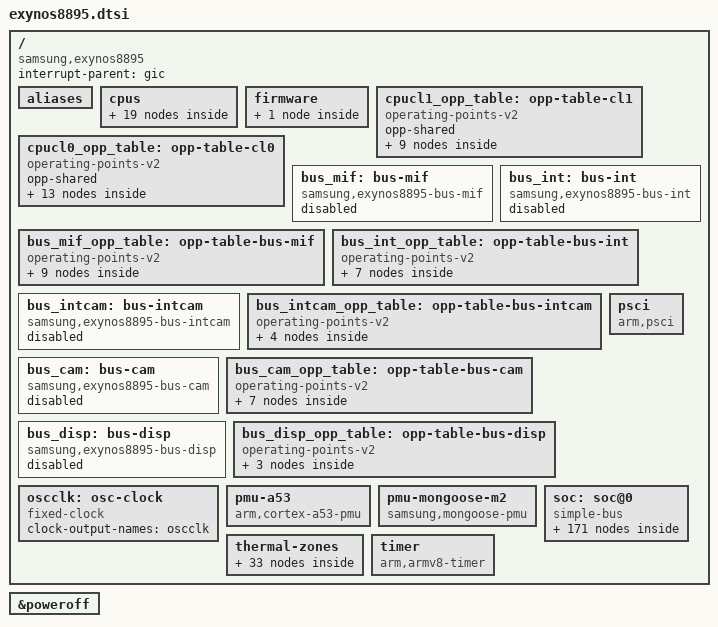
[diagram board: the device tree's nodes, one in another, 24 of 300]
// SPDX-License-Identifier: GPL-2.0 OR BSD-3-Clause
/*
 * Samsung's Exynos 8895 SoC device tree source
 *
 * Copyright (c) 2024, Ivaylo Ivanov <ivo.ivanov.ivanov1@gmail.com>
 */

#include <dt-bindings/clock/samsung,exynos8895.h>
#include <dt-bindings/clock/samsung,exynos8895-acpm.h>
#include <dt-bindings/interrupt-controller/arm-gic.h>
#include <dt-bindings/thermal/thermal.h>

/ {
	compatible = "samsung,exynos8895";
	#address-cells = <2>;
	#size-cells = <1>;

	interrupt-parent = <&gic>;

	aliases {
		pinctrl0 = &pinctrl_alive;
		pinctrl1 = &pinctrl_abox;
		pinctrl2 = &pinctrl_vts;
		pinctrl3 = &pinctrl_fsys0;
		pinctrl4 = &pinctrl_fsys1;
		pinctrl5 = &pinctrl_busc;
		pinctrl6 = &pinctrl_peric0;
		pinctrl7 = &pinctrl_peric1;
	};

	cpus {
		#address-cells = <1>;
		#size-cells = <0>;

		cpu-map {
			cluster0 {
				core0 { cpu = <&cpu0>; };
				core1 { cpu = <&cpu1>; };
				core2 { cpu = <&cpu2>; };
				core3 { cpu = <&cpu3>; };
			};

			cluster1 {
				core0 { cpu = <&cpu4>; };
				core1 { cpu = <&cpu5>; };
				core2 { cpu = <&cpu6>; };
				core3 { cpu = <&cpu7>; };
			};
		};

		/* Boot cluster (Cortex-A53, MPIDR Aff1=1) first: stock logical ids 0-3. */
		cpu0: cpu@100 {
			device_type = "cpu";
			compatible = "arm,cortex-a53";
			reg = <0x100>;			/* S:arch/arm64/boot/dts/exynos/exynos8895.dtsi:184, FDT:4274 */
			enable-method = "psci";		/* S:arch/arm64/boot/dts/exynos/exynos8895.dtsi:186 */
			capacity-dmips-mhz = <2048>;	/* S:arch/arm64/kernel/topology.c:207 */
		};

		cpu1: cpu@101 {
			device_type = "cpu";
			compatible = "arm,cortex-a53";
			reg = <0x101>;			/* S:arch/arm64/boot/dts/exynos/exynos8895.dtsi:194 */
			enable-method = "psci";
			capacity-dmips-mhz = <2048>;
		};

		cpu2: cpu@102 {
			device_type = "cpu";
			compatible = "arm,cortex-a53";
			reg = <0x102>;			/* S:arch/arm64/boot/dts/exynos/exynos8895.dtsi:203 */
			enable-method = "psci";
			capacity-dmips-mhz = <2048>;
		};

		cpu3: cpu@103 {
			device_type = "cpu";
			compatible = "arm,cortex-a53";
			reg = <0x103>;			/* S:arch/arm64/boot/dts/exynos/exynos8895.dtsi:212 */
			enable-method = "psci";
			capacity-dmips-mhz = <2048>;
		};

		/* Mongoose M2 cluster (MPIDR Aff1=0): stock logical ids 4-7. */
		cpu4: cpu@0 {
			device_type = "cpu";
			compatible = "samsung,mongoose-m2";	/* A:Documentation/devicetree/bindings/arm/cpus.yaml:222 */
			reg = <0x0>;			/* S:arch/arm64/boot/dts/exynos/exynos8895.dtsi:221, FDT:4317 */
			enable-method = "psci";		/* S:arch/arm64/boot/dts/exynos/exynos8895.dtsi:223 */
			capacity-dmips-mhz = <5035>;	/* S:arch/arm64/kernel/topology.c:205 */
		};

		cpu5: cpu@1 {
			device_type = "cpu";
			compatible = "samsung,mongoose-m2";
			reg = <0x1>;			/* S:arch/arm64/boot/dts/exynos/exynos8895.dtsi:231 */
			enable-method = "psci";
			capacity-dmips-mhz = <5035>;
		};

		cpu6: cpu@2 {
			device_type = "cpu";
			compatible = "samsung,mongoose-m2";
			reg = <0x2>;			/* S:arch/arm64/boot/dts/exynos/exynos8895.dtsi:240 */
			enable-method = "psci";
			capacity-dmips-mhz = <5035>;
		};

		cpu7: cpu@3 {
			device_type = "cpu";
			compatible = "samsung,mongoose-m2";
			reg = <0x3>;			/* S:arch/arm64/boot/dts/exynos/exynos8895.dtsi:249 */
			enable-method = "psci";
			capacity-dmips-mhz = <5035>;
		};
	};

	firmware {
		/*
		 * The APM's ACPM firmware interface (the stock acpm_ipc, acpm and
		 * acpm_dvfs nodes, S:arch/arm64/boot/dts/exynos/exynos8895.dtsi:2407-2438,
		 * FDT:6674-6701; their channel numbers are driver match data here).
		 * The PMIC child is the board's.
		 */
		acpm_ipc: power-management {
			compatible = "samsung,exynos8895-acpm-ipc";
			#clock-cells = <1>;	/* DVFS clocks, dt-bindings/clock/samsung,exynos8895-acpm.h */
			mboxes = <&ap2apm_mailbox>;
			shmem = <&apm_sram>;
			status = "disabled";
		};
	};

	/*
	 * Cortex-A53 cluster, cpus 0-3 = ACPM DVFS domain cpucl1. Levels: the ECT
	 * dvfs_cpucl1 table (sboot.bin SB+0x463cc); every ASV table (versions 1-8)
	 * enables L3..L11 = 1690000..455000 kHz, and stock "min-freq = <455000>;"
	 * (S:arch/arm64/boot/dts/exynos/exynos8895.dtsi:473). Nine levels = the
	 * nine A53 "current" entries (:189). No opp-microvolt: the APM applies
	 * the voltage itself, and there is no cpu-supply.
	 * clock-latency: S:drivers/cpufreq/exynos-acme.h:101 "#define TRANSITION_LATENCY 100000" (ns).
	 */
	cpucl1_opp_table: opp-table-cl1 {
		compatible = "operating-points-v2";
		opp-shared;

		opp-455000000 {
			opp-hz = /bits/ 64 <455000000>;
			clock-latency-ns = <100000>;
		};
		opp-598000000 {
			opp-hz = /bits/ 64 <598000000>;
			clock-latency-ns = <100000>;
		};
		opp-715000000 {
			opp-hz = /bits/ 64 <715000000>;
			clock-latency-ns = <100000>;
		};
		opp-832000000 {
			opp-hz = /bits/ 64 <832000000>;
			clock-latency-ns = <100000>;
		};
		opp-949000000 {
			opp-hz = /bits/ 64 <949000000>;
			clock-latency-ns = <100000>;
		};
		opp-1053000000 {
			/* ASV boot level L6 */
			opp-hz = /bits/ 64 <1053000000>;
			clock-latency-ns = <100000>;
		};
		opp-1248000000 {
			opp-hz = /bits/ 64 <1248000000>;
			clock-latency-ns = <100000>;
		};
		opp-1456000000 {
			opp-hz = /bits/ 64 <1456000000>;
			clock-latency-ns = <100000>;
		};
		opp-1690000000 {
			opp-hz = /bits/ 64 <1690000000>;
			clock-latency-ns = <100000>;
		};
	};

	/*
	 * Mongoose cluster, cpus 4-7 = ACPM DVFS domain cpucl0. Levels: the ECT
	 * dvfs_cpucl0 table (SB+0x462d4); ASV tables 3-8 enable L5..L17 =
	 * 2314000..741000 kHz (tables 1-2 stop at 2158000, and stock uses table 8
	 * for a version without a table, S:drivers/soc/samsung/cal-if/vclk.c:507-520),
	 * stock "min-freq = <741000>;" (S:arch/arm64/boot/dts/exynos/exynos8895.dtsi:518).
	 * 13 levels = the Mongoose "current" entries (:226). Drop opp-2314000000
	 * only if the fused ASV version (acpm-clk "asv_ver=") is 1 or 2.
	 * opp-microvolt feeds only the energy model of the IPA power actor (no
	 * cpu-supply, so the OPP core never applies it; the APM keeps its own
	 * voltage): ECT ASV block, dvfs_cpucl0, table version 8, group 0 (the
	 * highest voltage of each level in that table; Lnn = ECT level), chosen
	 * because ACK has no static-power term (spec/L2c_thermal.md 4.3).
	 */
	cpucl0_opp_table: opp-table-cl0 {
		compatible = "operating-points-v2";
		opp-shared;

		opp-741000000 {
			opp-hz = /bits/ 64 <741000000>;
			opp-microvolt = <681250>;	/* L17 */
			clock-latency-ns = <100000>;
		};
		opp-858000000 {
			opp-hz = /bits/ 64 <858000000>;
			opp-microvolt = <706250>;	/* L16 */
			clock-latency-ns = <100000>;
		};
		opp-962000000 {
			opp-hz = /bits/ 64 <962000000>;
			opp-microvolt = <725000>;	/* L15 */
			clock-latency-ns = <100000>;
		};
		opp-1066000000 {
			/* ASV boot level L14 */
			opp-hz = /bits/ 64 <1066000000>;
			opp-microvolt = <737500>;	/* L14 */
			clock-latency-ns = <100000>;
		};
		opp-1170000000 {
			opp-hz = /bits/ 64 <1170000000>;
			opp-microvolt = <756250>;	/* L13 */
			clock-latency-ns = <100000>;
		};
		opp-1261000000 {
			opp-hz = /bits/ 64 <1261000000>;
			opp-microvolt = <775000>;	/* L12 */
			clock-latency-ns = <100000>;
		};
		opp-1469000000 {
			opp-hz = /bits/ 64 <1469000000>;
			opp-microvolt = <825000>;	/* L11 */
			clock-latency-ns = <100000>;
		};
		opp-1703000000 {
			opp-hz = /bits/ 64 <1703000000>;
			opp-microvolt = <893750>;	/* L10 */
			clock-latency-ns = <100000>;
		};
		opp-1807000000 {
			opp-hz = /bits/ 64 <1807000000>;
			opp-microvolt = <925000>;	/* L9 */
			clock-latency-ns = <100000>;
		};
		opp-1937000000 {
			opp-hz = /bits/ 64 <1937000000>;
			opp-microvolt = <968750>;	/* L8 */
			clock-latency-ns = <100000>;
		};
		opp-2002000000 {
			opp-hz = /bits/ 64 <2002000000>;
			opp-microvolt = <987500>;	/* L7 */
			clock-latency-ns = <100000>;
		};
		opp-2158000000 {
			opp-hz = /bits/ 64 <2158000000>;
			opp-microvolt = <1050000>;	/* L6 */
			clock-latency-ns = <100000>;
		};
		opp-2314000000 {
			opp-hz = /bits/ 64 <2314000000>;
			opp-microvolt = <1118750>;	/* L5 */
			clock-latency-ns = <100000>;
		};
	};

	/*
	 * Bus DVFS domains (spec L2b 4.1): stock devfreq_{mif,int,intcam,disp,cam}
	 * (FDT:6712-6805). Levels = ECT DVFS levels inside the ASV-enabled range,
	 * the same for ASV tables 1-8 (sboot.bin ECT, spec L2b 0.4). The rate is
	 * set through the ACPM DVFS clock (FREQ_REQ on ACPM channel 0).
	 */
	bus_mif: bus-mif {
		compatible = "samsung,exynos8895-bus-mif";
		clocks = <&acpm_ipc EXYNOS8895_CLK_ACPM_DVFS_MIF>;	/* dfs_id 0xb040000, FDT:6728 */
		operating-points-v2 = <&bus_mif_opp_table>;
		status = "disabled";
	};

	bus_mif_opp_table: opp-table-bus-mif {
		compatible = "operating-points-v2";

		/* ECT dvfs_mif L10..L2 (SB:0x46508); ASV level_en L2-L10 in tables 1-8 */
		opp-286000000 { opp-hz = /bits/ 64 <286000000>; };
		opp-421000000 { opp-hz = /bits/ 64 <421000000>; };
		opp-546000000 { opp-hz = /bits/ 64 <546000000>; };
		opp-676000000 { opp-hz = /bits/ 64 <676000000>; };
		opp-845000000 { opp-hz = /bits/ 64 <845000000>; };
		opp-1014000000 { opp-hz = /bits/ 64 <1014000000>; };
		opp-1352000000 { opp-hz = /bits/ 64 <1352000000>; };
		opp-1540000000 { opp-hz = /bits/ 64 <1540000000>; };
		opp-1794000000 { opp-hz = /bits/ 64 <1794000000>; };
	};

	bus_int: bus-int {
		compatible = "samsung,exynos8895-bus-int";
		clocks = <&acpm_ipc EXYNOS8895_CLK_ACPM_DVFS_INT>;	/* dfs_id 0xb040001, FDT:6748 */
		operating-points-v2 = <&bus_int_opp_table>;
		status = "disabled";
	};

	bus_int_opp_table: opp-table-bus-int {
		compatible = "operating-points-v2";

		/* ECT dvfs_int L6..L0 (SB:0x46654); all enabled in ASV tables 1-8 */
		opp-107000000 { opp-hz = /bits/ 64 <107000000>; };
		opp-178000000 { opp-hz = /bits/ 64 <178000000>; };
		opp-267000000 { opp-hz = /bits/ 64 <267000000>; };
		opp-333000000 { opp-hz = /bits/ 64 <333000000>; };
		opp-400000000 { opp-hz = /bits/ 64 <400000000>; };
		opp-533000000 { opp-hz = /bits/ 64 <533000000>; };
		opp-667000000 { opp-hz = /bits/ 64 <667000000>; };
	};

	bus_intcam: bus-intcam {
		compatible = "samsung,exynos8895-bus-intcam";
		clocks = <&acpm_ipc EXYNOS8895_CLK_ACPM_DVFS_INTCAM>;	/* dfs_id 0xb040005, FDT:6768 */
		operating-points-v2 = <&bus_intcam_opp_table>;
		status = "disabled";
	};

	bus_intcam_opp_table: opp-table-bus-intcam {
		compatible = "operating-points-v2";

		/* ECT dvfs_intcam L3..L0 (SB:0x468a8); all enabled */
		opp-640000000 { opp-hz = /bits/ 64 <640000000>; };
		opp-670000000 { opp-hz = /bits/ 64 <670000000>; };
		opp-680000000 { opp-hz = /bits/ 64 <680000000>; };
		opp-690000000 { opp-hz = /bits/ 64 <690000000>; };
	};

	bus_cam: bus-cam {
		compatible = "samsung,exynos8895-bus-cam";
		clocks = <&acpm_ipc EXYNOS8895_CLK_ACPM_DVFS_CAM>;	/* dfs_id 0xb040006, FDT:6804 */
		operating-points-v2 = <&bus_cam_opp_table>;
		status = "disabled";
	};

	bus_cam_opp_table: opp-table-bus-cam {
		compatible = "operating-points-v2";

		/* ECT dvfs_cam L6..L0 (SB:0x46934); all enabled */
		opp-630000000 { opp-hz = /bits/ 64 <630000000>; };
		opp-640000000 { opp-hz = /bits/ 64 <640000000>; };
		opp-650000000 { opp-hz = /bits/ 64 <650000000>; };
		opp-660000000 { opp-hz = /bits/ 64 <660000000>; };
		opp-670000000 { opp-hz = /bits/ 64 <670000000>; };
		opp-680000000 { opp-hz = /bits/ 64 <680000000>; };
		opp-690000000 { opp-hz = /bits/ 64 <690000000>; };
	};

	bus_disp: bus-disp {
		compatible = "samsung,exynos8895-bus-disp";
		clocks = <&acpm_ipc EXYNOS8895_CLK_ACPM_DVFS_DISP>;	/* dfs_id 0xb040007, FDT:6786 */
		operating-points-v2 = <&bus_disp_opp_table>;
		status = "disabled";
	};

	bus_disp_opp_table: opp-table-bus-disp {
		compatible = "operating-points-v2";

		/* ECT dvfs_disp L3..L1 (SB:0x46c48); ASV level_en L1-L3 in tables 1-8 */
		opp-214000000 { opp-hz = /bits/ 64 <214000000>; };
		opp-356000000 { opp-hz = /bits/ 64 <356000000>; };
		opp-533000000 { opp-hz = /bits/ 64 <533000000>; };
	};

	oscclk: osc-clock {
		compatible = "fixed-clock";
		#clock-cells = <0>;
		clock-output-names = "oscclk";
	};

	pmu-a53 {
		compatible = "arm,cortex-a53-pmu";
		interrupts = <GIC_SPI 24 IRQ_TYPE_LEVEL_HIGH>,
			     <GIC_SPI 25 IRQ_TYPE_LEVEL_HIGH>,
			     <GIC_SPI 26 IRQ_TYPE_LEVEL_HIGH>,
			     <GIC_SPI 27 IRQ_TYPE_LEVEL_HIGH>;
		interrupt-affinity = <&cpu0>,
				     <&cpu1>,
				     <&cpu2>,
				     <&cpu3>;
	};

	pmu-mongoose-m2 {
		compatible = "samsung,mongoose-pmu";
		interrupts = <GIC_SPI 40 IRQ_TYPE_LEVEL_HIGH>,
			     <GIC_SPI 41 IRQ_TYPE_LEVEL_HIGH>,
			     <GIC_SPI 42 IRQ_TYPE_LEVEL_HIGH>,
			     <GIC_SPI 43 IRQ_TYPE_LEVEL_HIGH>;
		interrupt-affinity = <&cpu4>,
				     <&cpu5>,
				     <&cpu6>,
				     <&cpu7>;
	};

	psci {
		compatible = "arm,psci";
		method = "smc";
		cpu_off = <0x84000002>;
		cpu_on = <0xc4000003>;
		cpu_suspend = <0xc4000001>;
	};

	soc: soc@0 {
		compatible = "simple-bus";
		ranges = <0x0 0x0 0x0 0x20000000>;

		#address-cells = <1>;
		#size-cells = <1>;

		chipid@10000000 {
			compatible = "samsung,exynos8895-chipid",
				     "samsung,exynos850-chipid";
			reg = <0x10000000 0x24>;
		};

		cmu_peris: clock-controller@10010000 {
			compatible = "samsung,exynos8895-cmu-peris";
			reg = <0x10010000 0x8000>;
			#clock-cells = <1>;
			clocks = <&oscclk>,
				 <&cmu_top CLK_DOUT_CMU_PERIS_BUS>;
			clock-names = "oscclk", "bus";
		};

		timer@10040000 {
			compatible = "samsung,exynos8895-mct",
				     "samsung,exynos4210-mct";
			reg = <0x10040000 0x800>;
			clocks = <&oscclk>, <&cmu_peris CLK_GOUT_PERIS_MCT_PCLK>;
			clock-names = "fin_pll", "mct";
			interrupts = <GIC_SPI 455 IRQ_TYPE_LEVEL_HIGH>,
				     <GIC_SPI 456 IRQ_TYPE_LEVEL_HIGH>,
				     <GIC_SPI 457 IRQ_TYPE_LEVEL_HIGH>,
				     <GIC_SPI 458 IRQ_TYPE_LEVEL_HIGH>,
				     <GIC_SPI 459 IRQ_TYPE_LEVEL_HIGH>,
				     <GIC_SPI 460 IRQ_TYPE_LEVEL_HIGH>,
				     <GIC_SPI 461 IRQ_TYPE_LEVEL_HIGH>,
				     <GIC_SPI 462 IRQ_TYPE_LEVEL_HIGH>,
				     <GIC_SPI 463 IRQ_TYPE_LEVEL_HIGH>,
				     <GIC_SPI 464 IRQ_TYPE_LEVEL_HIGH>,
				     <GIC_SPI 465 IRQ_TYPE_LEVEL_HIGH>,
				     <GIC_SPI 466 IRQ_TYPE_LEVEL_HIGH>;
		};

		watchdog: watchdog@10060000 {
			compatible = "samsung,exynos8895-wdt";
			reg = <0x10060000 0x100>;	/* S:arch/arm64/boot/dts/exynos/exynos8895.dtsi:3169; FDT:7681 */
			interrupts = <GIC_SPI 454 IRQ_TYPE_LEVEL_HIGH>;	/* S:...:3170 <0 454 0>; FDT:7682 0x1c6 */
			/*
			 * stock "gate_watchdog" = UMUX_CLKCMU_PERIS_BUS (the PERIS bus user mux),
			 * "rate_watchdog" = OSCCLK 26 MHz: S:...:3171-3172
			 */
			clocks = <&cmu_peris CLK_MOUT_PERIS_BUS_USER>, <&oscclk>;
			clock-names = "watchdog", "watchdog_src";
			samsung,syscon-phandle = <&pmu_system_controller>;	/* S:...:3174 */
			timeout-sec = <30>;	/* S:...:3173; FDT:7685 0x1e */
			status = "disabled";
		};

		/*
		 * Four TMU instances on two register blocks, as stock
		 * (S:arch/arm64/boot/dts/exynos/exynos8895.dtsi:4537-4591, FDT:9339-9434):
		 * the node names differ because dtc merges same-named siblings; the
		 * shared unit address is a W=1 warning only. APB clock: PERIS
		 * BUSIF_TMU at PERIS+0x2020 (CAL:cmucal-sfr.c:1903).
		 */
		tmu_big: tmu-big@10080000 {
			compatible = "samsung,exynos8895-tmu";
			reg = <0x10080000 0x400>;		/* S:...exynos8895.dtsi:4539 */
			interrupts = <GIC_SPI 451 IRQ_TYPE_LEVEL_HIGH>;	/* :4540 "<0 451 0>"; FDT:9342 <0x1c3> */
			clocks = <&cmu_peris CLK_GOUT_PERIS_BUSIF_TMU_PCLK>;
			clock-names = "tmu_apbif";
			samsung,tmu-sensors = <0x3d>;		/* :4543 "sensors = <61>;" */
			samsung,tmu-sensing-mode = "balance";	/* :4544 */
			/* stock mngs-thermal power_allocator gains, FDT:9445-9449 (mW/C, mW, C) */
			samsung,ipa-k-po = <100>;		/* k_po = <0x64> */
			samsung,ipa-k-pu = <85>;		/* k_pu = <0x55> */
			samsung,ipa-k-i = <100>;		/* k_i = <0x64> */
			samsung,ipa-integral-max = <1500>;	/* i_max = <0x5dc> */
			samsung,ipa-integral-cutoff = <28>;	/* integral_cutoff = <0x1c> */
			/*
			 * FDT:9347-9349 hotplug_enable, in <0x5b>, out <0x60> (C); the CPUs
			 * above NR_HOTPLUG_CPUS 4 (S:drivers/thermal/samsung/exynos_tmu.h:30)
			 */
			samsung,hotplug-cpus = <&cpu4>, <&cpu5>, <&cpu6>, <&cpu7>;
			samsung,hotplug-out-temp = <96000>;
			samsung,hotplug-in-temp = <91000>;
			#thermal-sensor-cells = <0>;
			status = "disabled";
		};

		tmu_little: tmu-little@10080000 {
			compatible = "samsung,exynos8895-tmu";
			reg = <0x10080000 0x400>;		/* :4553 */
			interrupts = <GIC_SPI 451 IRQ_TYPE_LEVEL_HIGH>;	/* :4554 */
			clocks = <&cmu_peris CLK_GOUT_PERIS_BUSIF_TMU_PCLK>;
			clock-names = "tmu_apbif";
			samsung,tmu-sensors = <0x02>;		/* :4557 "sensors = <2>;" */
			samsung,tmu-sensing-mode = "max";	/* :4558 */
			#thermal-sensor-cells = <0>;
			status = "disabled";
		};

		tmu_gpu: tmu-gpu@10084000 {
			compatible = "samsung,exynos8895-tmu";
			reg = <0x10084000 0x400>;		/* :4564 */
			interrupts = <GIC_SPI 452 IRQ_TYPE_LEVEL_HIGH>;	/* :4565 "<0 452 0>" */
			clocks = <&cmu_peris CLK_GOUT_PERIS_BUSIF_TMU_PCLK>;
			clock-names = "tmu_apbif";
			samsung,tmu-sensors = <0x01>;		/* :4568 "sensors = <1>;" */
			samsung,tmu-sensing-mode = "max";	/* :4569 */
			/* stock GPU power_allocator gains, FDT:9620-9624 (mW/C, mW, C) */
			samsung,ipa-k-po = <60>;		/* k_po = <0x3c> */
			samsung,ipa-k-pu = <100>;		/* k_pu = <0x64> */
			samsung,ipa-k-i = <50>;			/* k_i = <0x32> */
			samsung,ipa-integral-max = <500>;	/* i_max = <0x1f4> */
			samsung,ipa-integral-cutoff = <10>;	/* integral_cutoff = <0x0a> */
			#thermal-sensor-cells = <0>;
			status = "disabled";
		};

		tmu_isp: tmu-isp@10084000 {
			compatible = "samsung,exynos8895-tmu";
			reg = <0x10084000 0x400>;		/* :4584 */
			interrupts = <GIC_SPI 452 IRQ_TYPE_LEVEL_HIGH>;	/* :4585 */
			clocks = <&cmu_peris CLK_GOUT_PERIS_BUSIF_TMU_PCLK>;
			clock-names = "tmu_apbif";
			samsung,tmu-sensors = <0x06>;		/* :4588 "sensors = <6>;" */
			samsung,tmu-sensing-mode = "max";	/* :4589 */
			#thermal-sensor-cells = <0>;
			status = "disabled";
		};

		gic: interrupt-controller@10201000 {
			compatible = "arm,gic-400";
			reg = <0x10201000 0x1000>,
			      <0x10202000 0x1000>,
			      <0x10204000 0x2000>,
			      <0x10206000 0x2000>;
			#interrupt-cells = <3>;
			interrupt-controller;
			interrupts = <GIC_PPI 9 (GIC_CPU_MASK_SIMPLE(8) |
						 IRQ_TYPE_LEVEL_HIGH)>;
			#address-cells = <0>;
			#size-cells = <1>;
		};

		cmu_peric0: clock-controller@10400000 {
			compatible = "samsung,exynos8895-cmu-peric0";
			reg = <0x10400000 0x8000>;
			#clock-cells = <1>;
			clocks = <&oscclk>,
				 <&cmu_top CLK_DOUT_CMU_PERIC0_BUS>,
				 <&cmu_top CLK_DOUT_CMU_PERIC0_UART_DBG>,
				 <&cmu_top CLK_DOUT_CMU_PERIC0_USI00>,
				 <&cmu_top CLK_DOUT_CMU_PERIC0_USI01>,
				 <&cmu_top CLK_DOUT_CMU_PERIC0_USI02>,
				 <&cmu_top CLK_DOUT_CMU_PERIC0_USI03>;
			clock-names = "oscclk", "bus", "uart", "usi0",
				      "usi1", "usi2", "usi3";
		};

		syscon_peric0: syscon@10420000 {
			compatible = "samsung,exynos8895-peric0-sysreg", "syscon";
			reg = <0x10420000 0x2000>;
			clocks = <&cmu_peric0 CLK_GOUT_PERIC0_SYSREG_PERIC0_PCLK>;
		};

		serial_0: serial@10430000 {
			compatible = "samsung,exynos8895-uart";
			reg = <0x10430000 0x100>;
			clocks = <&cmu_peric0 CLK_GOUT_PERIC0_UART_DBG_PCLK>,
				 <&cmu_peric0 CLK_GOUT_PERIC0_UART_DBG_EXT_UCLK>;
			clock-names = "uart", "clk_uart_baud0";
			interrupts = <GIC_SPI 385 IRQ_TYPE_LEVEL_HIGH>;
			pinctrl-names = "default";
			pinctrl-0 = <&uart0_bus>;
			samsung,uart-fifosize = <256>;
			status = "disabled";
		};

		usi0: usi@10440000 {
			compatible = "samsung,exynos8895-usi";
			ranges = <0x0 0x10440000 0x11000>;
			clocks = <&cmu_peric0 CLK_GOUT_PERIC0_USI00_I_PCLK>,
				 <&cmu_peric0 CLK_GOUT_PERIC0_USI00_I_SCLK_USI>;
			clock-names = "pclk", "ipclk";
			#address-cells = <1>;
			#size-cells = <1>;
			samsung,sysreg = <&syscon_peric0 0x1000>;
			status = "disabled";

			hsi2c_5: i2c@0 {
				compatible = "samsung,exynos8895-hsi2c";
				reg = <0x0 0x1000>;
				clocks = <&cmu_peric0 CLK_GOUT_PERIC0_USI00_I_PCLK>;
				clock-names = "hsi2c";
				interrupts = <GIC_SPI 364 IRQ_TYPE_LEVEL_HIGH>;
				pinctrl-0 = <&hsi2c5_bus>;
				pinctrl-names = "default";
				status = "disabled";
			};

			serial_2: serial@0 {
				compatible = "samsung,exynos8895-uart";
				reg = <0x0 0x100>;
				clocks = <&cmu_peric0 CLK_GOUT_PERIC0_USI00_I_PCLK>,
					 <&cmu_peric0 CLK_GOUT_PERIC0_USI00_I_SCLK_USI>;
				clock-names = "uart", "clk_uart_baud0";
				interrupts = <GIC_SPI 366 IRQ_TYPE_LEVEL_HIGH>;
				pinctrl-0 = <&uart2_bus>;
				pinctrl-names = "default";
				samsung,uart-fifosize = <64>;
				status = "disabled";
			};

			spi_2: spi@0 {
				compatible = "samsung,exynos8895-spi",
					     "samsung,exynos850-spi";
				reg = <0x0 0x100>;
				clocks = <&cmu_peric0 CLK_GOUT_PERIC0_USI00_I_PCLK>,
					 <&cmu_peric0 CLK_GOUT_PERIC0_USI00_I_SCLK_USI>;
				clock-names = "spi", "spi_busclk0";
				interrupts = <GIC_SPI 367 IRQ_TYPE_LEVEL_HIGH>;
				pinctrl-0 = <&spi2_bus>;
				pinctrl-names = "default";
				#address-cells = <1>;
				#size-cells = <0>;
				status = "disabled";
			};

			hsi2c_6: i2c@10000 {
				compatible = "samsung,exynos8895-hsi2c";
				reg = <0x10000 0x1000>;
				clocks = <&cmu_peric0 CLK_GOUT_PERIC0_USI00_I_PCLK>;
				clock-names = "hsi2c";
				interrupts = <GIC_SPI 365 IRQ_TYPE_LEVEL_HIGH>;
				pinctrl-0 = <&hsi2c6_bus>;
				pinctrl-names = "default";
				status = "disabled";
			};
		};

		usi1: usi@10460000 {
			compatible = "samsung,exynos8895-usi";
			ranges = <0x0 0x10460000 0x11000>;
			clocks = <&cmu_peric0 CLK_GOUT_PERIC0_USI01_I_PCLK>,
				 <&cmu_peric0 CLK_GOUT_PERIC0_USI01_I_SCLK_USI>;
			clock-names = "pclk", "ipclk";
			#address-cells = <1>;
			#size-cells = <1>;
			samsung,sysreg = <&syscon_peric0 0x1004>;
			status = "disabled";

			hsi2c_7: i2c@0 {
				compatible = "samsung,exynos8895-hsi2c";
				reg = <0x0 0x1000>;
				clocks = <&cmu_peric0 CLK_GOUT_PERIC0_USI01_I_PCLK>;
				clock-names = "hsi2c";
				interrupts = <GIC_SPI 368 IRQ_TYPE_LEVEL_HIGH>;
				pinctrl-0 = <&hsi2c5_bus>;
				pinctrl-names = "default";
				status = "disabled";
			};

			serial_3: serial@0 {
				compatible = "samsung,exynos8895-uart";
				reg = <0x0 0x100>;
				clocks = <&cmu_peric0 CLK_GOUT_PERIC0_USI01_I_PCLK>,
					 <&cmu_peric0 CLK_GOUT_PERIC0_USI01_I_SCLK_USI>;
				clock-names = "uart", "clk_uart_baud0";
				interrupts = <GIC_SPI 370 IRQ_TYPE_LEVEL_HIGH>;
				pinctrl-0 = <&uart3_bus>;
				pinctrl-names = "default";
				samsung,uart-fifosize = <64>;
				status = "disabled";
			};

			spi_3: spi@0 {
				compatible = "samsung,exynos8895-spi",
					     "samsung,exynos850-spi";
				reg = <0x0 0x100>;
				clocks = <&cmu_peric0 CLK_GOUT_PERIC0_USI01_I_PCLK>,
					 <&cmu_peric0 CLK_GOUT_PERIC0_USI01_I_SCLK_USI>;
				clock-names = "spi", "spi_busclk0";
				interrupts = <GIC_SPI 371 IRQ_TYPE_LEVEL_HIGH>;
				pinctrl-0 = <&spi3_bus>;
				pinctrl-names = "default";
				#address-cells = <1>;
				#size-cells = <0>;
				status = "disabled";
			};

			hsi2c_8: i2c@10000 {
				compatible = "samsung,exynos8895-hsi2c";
				reg = <0x10000 0x1000>;
				clocks = <&cmu_peric0 CLK_GOUT_PERIC0_USI01_I_PCLK>;
				clock-names = "hsi2c";
				interrupts = <GIC_SPI 369 IRQ_TYPE_LEVEL_HIGH>;
				pinctrl-0 = <&hsi2c8_bus>;
				pinctrl-names = "default";
				status = "disabled";
			};
		};

		usi2: usi@10480000 {
			compatible = "samsung,exynos8895-usi";
			ranges = <0x0 0x10480000 0x11000>;
			clocks = <&cmu_peric0 CLK_GOUT_PERIC0_USI02_I_PCLK>,
				 <&cmu_peric0 CLK_GOUT_PERIC0_USI02_I_SCLK_USI>;
			clock-names = "pclk", "ipclk";
			#address-cells = <1>;
			#size-cells = <1>;
			samsung,sysreg = <&syscon_peric0 0x1008>;
			status = "disabled";

			hsi2c_9: i2c@0 {
				compatible = "samsung,exynos8895-hsi2c";
				reg = <0x0 0x1000>;
				clocks = <&cmu_peric0 CLK_GOUT_PERIC0_USI02_I_PCLK>;
				clock-names = "hsi2c";
				interrupts = <GIC_SPI 372 IRQ_TYPE_LEVEL_HIGH>;
				pinctrl-0 = <&hsi2c9_bus>;
				pinctrl-names = "default";
				status = "disabled";
			};

			serial_4: serial@0 {
				compatible = "samsung,exynos8895-uart";
				reg = <0x0 0x100>;
				clocks = <&cmu_peric0 CLK_GOUT_PERIC0_USI02_I_PCLK>,
					 <&cmu_peric0 CLK_GOUT_PERIC0_USI02_I_SCLK_USI>;
				clock-names = "uart", "clk_uart_baud0";
				interrupts = <GIC_SPI 374 IRQ_TYPE_LEVEL_HIGH>;
				pinctrl-0 = <&uart4_bus>;
				pinctrl-names = "default";
				samsung,uart-fifosize = <64>;
				status = "disabled";
			};

			spi_4: spi@0 {
				compatible = "samsung,exynos8895-spi",
					     "samsung,exynos850-spi";
				reg = <0x0 0x100>;
				clocks = <&cmu_peric0 CLK_GOUT_PERIC0_USI02_I_PCLK>,
					 <&cmu_peric0 CLK_GOUT_PERIC0_USI02_I_SCLK_USI>;
				clock-names = "spi", "spi_busclk0";
				interrupts = <GIC_SPI 375 IRQ_TYPE_LEVEL_HIGH>;
				pinctrl-0 = <&spi4_bus>;
				pinctrl-names = "default";
				#address-cells = <1>;
				#size-cells = <0>;
				status = "disabled";
			};

			hsi2c_10: i2c@10000 {
				compatible = "samsung,exynos8895-hsi2c";
				reg = <0x10000 0x1000>;
				clocks = <&cmu_peric0 CLK_GOUT_PERIC0_USI02_I_PCLK>;
				clock-names = "hsi2c";
				interrupts = <GIC_SPI 373 IRQ_TYPE_LEVEL_HIGH>;
				pinctrl-0 = <&hsi2c10_bus>;
				pinctrl-names = "default";
				status = "disabled";
			};
		};

		usi3: usi@104a0000 {
			compatible = "samsung,exynos8895-usi";
			ranges = <0x0 0x104a0000 0x11000>;
			clocks = <&cmu_peric0 CLK_GOUT_PERIC0_USI03_I_PCLK>,
				 <&cmu_peric0 CLK_GOUT_PERIC0_USI03_I_SCLK_USI>;
			clock-names = "pclk", "ipclk";
			#address-cells = <1>;
			#size-cells = <1>;
			samsung,sysreg = <&syscon_peric0 0x100c>;
			status = "disabled";

			hsi2c_11: i2c@0 {
				compatible = "samsung,exynos8895-hsi2c";
				reg = <0x0 0x1000>;
				clocks = <&cmu_peric0 CLK_GOUT_PERIC0_USI03_I_PCLK>;
				clock-names = "hsi2c";
				interrupts = <GIC_SPI 376 IRQ_TYPE_LEVEL_HIGH>;
				pinctrl-0 = <&hsi2c11_bus>;
				pinctrl-names = "default";
				status = "disabled";
			};

			serial_5: serial@0 {
				compatible = "samsung,exynos8895-uart";
				reg = <0x0 0x100>;
				clocks = <&cmu_peric0 CLK_GOUT_PERIC0_USI03_I_PCLK>,
					 <&cmu_peric0 CLK_GOUT_PERIC0_USI03_I_SCLK_USI>;
				clock-names = "uart", "clk_uart_baud0";
				interrupts = <GIC_SPI 378 IRQ_TYPE_LEVEL_HIGH>;
				pinctrl-0 = <&uart5_bus>;
				pinctrl-names = "default";
				samsung,uart-fifosize = <64>;
				status = "disabled";
			};

			spi_5: spi@0 {
				compatible = "samsung,exynos8895-spi",
					     "samsung,exynos850-spi";
				reg = <0x0 0x100>;
				clocks = <&cmu_peric0 CLK_GOUT_PERIC0_USI03_I_PCLK>,
					 <&cmu_peric0 CLK_GOUT_PERIC0_USI03_I_SCLK_USI>;
				clock-names = "spi", "spi_busclk0";
				interrupts = <GIC_SPI 379 IRQ_TYPE_LEVEL_HIGH>;
				pinctrl-0 = <&spi5_bus>;
				pinctrl-names = "default";
				#address-cells = <1>;
				#size-cells = <0>;
				status = "disabled";
			};

			hsi2c_12: i2c@10000 {
				compatible = "samsung,exynos8895-hsi2c";
				reg = <0x10000 0x1000>;
				clocks = <&cmu_peric0 CLK_GOUT_PERIC0_USI03_I_PCLK>;
				clock-names = "hsi2c";
				interrupts = <GIC_SPI 377 IRQ_TYPE_LEVEL_HIGH>;
				pinctrl-0 = <&hsi2c12_bus>;
				pinctrl-names = "default";
				status = "disabled";
			};
		};

		pwm: pwm@104c0000 {
			compatible = "samsung,s3c6400-pwm";	/* FDT:7741 (kept: 6.18 s3c64xx variant is the correct TCFG1 encoding, C-1) */
			reg = <0x104c0000 0x1000>;		/* FDT:7742 */
			samsung,pwm-outputs = <0>, <1>, <2>, <3>, <4>;	/* FDT:7743 */
			#pwm-cells = <3>;			/* FDT:7744 */
			clocks = <&cmu_peric0 CLK_GOUT_PERIC0_PWM_I_PCLK_S0>, <&oscclk>;
			clock-names = "timers", "pwm-ref";	/* timers = PWM APB gate (id 12, A:include/dt-bindings/clock/samsung,exynos8895.h:372).
								   Stock gate_timers = <0x21 0xd8> (FDT:7745-7746) = 216 = CLK_PERIC0_BASE 200 + 16 =
								   UMUX_CLKCMU_PERIC0_BUS (S:include/dt-bindings/clock/exynos8895.h:73,90), the PERIC0 bus
								   user mux feeding GATE_PWM (S:drivers/clk/samsung/clk-exynos8895.c:357,367); the ACK leaf
								   gate is the equivalent consumer handle (verifier V-5);
								   pwm-ref = 26 MHz = stock "pwm-clock" (fixed 1:1 of fin_pll, :700) (5.8) */
			status = "disabled";
		};

		pinctrl_peric0: pinctrl@104d0000 {
			compatible = "samsung,exynos8895-pinctrl";
			reg = <0x104d0000 0x1000>;
			interrupts = <GIC_SPI 386 IRQ_TYPE_LEVEL_HIGH>;
		};

		cmu_peric1: clock-controller@10800000 {
			compatible = "samsung,exynos8895-cmu-peric1";
			reg = <0x10800000 0x8000>;
			#clock-cells = <1>;
			clocks = <&oscclk>,
				 <&cmu_top CLK_DOUT_CMU_PERIC1_BUS>,
				 <&cmu_top CLK_DOUT_CMU_PERIC1_SPEEDY2>,
				 <&cmu_top CLK_DOUT_CMU_PERIC1_SPI_CAM0>,
				 <&cmu_top CLK_DOUT_CMU_PERIC1_SPI_CAM1>,
				 <&cmu_top CLK_DOUT_CMU_PERIC1_UART_BT>,
				 <&cmu_top CLK_DOUT_CMU_PERIC1_USI04>,
				 <&cmu_top CLK_DOUT_CMU_PERIC1_USI05>,
				 <&cmu_top CLK_DOUT_CMU_PERIC1_USI06>,
				 <&cmu_top CLK_DOUT_CMU_PERIC1_USI07>,
				 <&cmu_top CLK_DOUT_CMU_PERIC1_USI08>,
				 <&cmu_top CLK_DOUT_CMU_PERIC1_USI09>,
				 <&cmu_top CLK_DOUT_CMU_PERIC1_USI10>,
				 <&cmu_top CLK_DOUT_CMU_PERIC1_USI11>,
				 <&cmu_top CLK_DOUT_CMU_PERIC1_USI12>,
				 <&cmu_top CLK_DOUT_CMU_PERIC1_USI13>;
			clock-names = "oscclk", "bus", "speedy", "cam0",
				      "cam1", "uart", "usi4", "usi5",
				      "usi6", "usi7", "usi8", "usi9",
				      "usi10", "usi11", "usi12", "usi13";
		};

		syscon_peric1: syscon@10820000 {
			compatible = "samsung,exynos8895-peric1-sysreg", "syscon";
			reg = <0x10820000 0x2000>;
			clocks = <&cmu_peric1 CLK_GOUT_PERIC1_SYSREG_PERIC1_PCLK>;
		};

		serial_1: serial@10830000 {
			compatible = "samsung,exynos8895-uart";
			reg = <0x10830000 0x100>;
			clocks = <&cmu_peric1 CLK_GOUT_PERIC1_UART_BT_PCLK>,
				 <&cmu_peric1 CLK_GOUT_PERIC1_UART_BT_EXT_UCLK>;
			clock-names = "uart", "clk_uart_baud0";
			interrupts = <GIC_SPI 389 IRQ_TYPE_LEVEL_HIGH>;
			pinctrl-names = "default";
			pinctrl-0 = <&uart1_bus>;
			samsung,uart-fifosize = <256>;
			status = "disabled";
		};

		usi4: usi@10840000 {
			compatible = "samsung,exynos8895-usi";
			ranges = <0x0 0x10840000 0x11000>;
			clocks = <&cmu_peric1 CLK_GOUT_PERIC1_USI04_I_PCLK>,
				 <&cmu_peric1 CLK_GOUT_PERIC1_USI04_I_SCLK_USI>;
			clock-names = "pclk", "ipclk";
			#address-cells = <1>;
			#size-cells = <1>;
			samsung,sysreg = <&syscon_peric1 0x1008>;
			status = "disabled";

			hsi2c_13: i2c@0 {
				compatible = "samsung,exynos8895-hsi2c";
				reg = <0x0 0x1000>;
				clocks = <&cmu_peric1 CLK_GOUT_PERIC1_USI04_I_PCLK>;
				clock-names = "hsi2c";
				interrupts = <GIC_SPI 390 IRQ_TYPE_LEVEL_HIGH>;
				pinctrl-0 = <&hsi2c13_bus>;
				pinctrl-names = "default";
				status = "disabled";
			};

			serial_6: serial@0 {
				compatible = "samsung,exynos8895-uart";
				reg = <0x0 0x100>;
				clocks = <&cmu_peric1 CLK_GOUT_PERIC1_USI04_I_PCLK>,
					 <&cmu_peric1 CLK_GOUT_PERIC1_USI04_I_SCLK_USI>;
				clock-names = "uart", "clk_uart_baud0";
				interrupts = <GIC_SPI 392 IRQ_TYPE_LEVEL_HIGH>;
				pinctrl-0 = <&uart6_bus>;
				pinctrl-names = "default";
				samsung,uart-fifosize = <64>;
				status = "disabled";
			};

			spi_6: spi@0 {
				compatible = "samsung,exynos8895-spi",
					     "samsung,exynos850-spi";
				reg = <0x0 0x100>;
				clocks = <&cmu_peric1 CLK_GOUT_PERIC1_USI04_I_PCLK>,
					 <&cmu_peric1 CLK_GOUT_PERIC1_USI04_I_SCLK_USI>;
				clock-names = "spi", "spi_busclk0";
				interrupts = <GIC_SPI 393 IRQ_TYPE_LEVEL_HIGH>;
				pinctrl-0 = <&spi6_bus>;
				pinctrl-names = "default";
				#address-cells = <1>;
				#size-cells = <0>;
				status = "disabled";
			};

			hsi2c_14: i2c@10000 {
				compatible = "samsung,exynos8895-hsi2c";
				reg = <0x10000 0x1000>;
				clocks = <&cmu_peric1 CLK_GOUT_PERIC1_USI04_I_PCLK>;
				clock-names = "hsi2c";
				interrupts = <GIC_SPI 391 IRQ_TYPE_LEVEL_HIGH>;
				pinctrl-0 = <&hsi2c14_bus>;
				pinctrl-names = "default";
				status = "disabled";
			};
		};

		usi5: usi@10860000 {
			compatible = "samsung,exynos8895-usi";
			ranges = <0x0 0x10860000 0x11000>;
			clocks = <&cmu_peric1 CLK_GOUT_PERIC1_USI05_I_PCLK>,
				 <&cmu_peric1 CLK_GOUT_PERIC1_USI05_I_SCLK_USI>;
			clock-names = "pclk", "ipclk";
			#address-cells = <1>;
			#size-cells = <1>;
			samsung,sysreg = <&syscon_peric1 0x100c>;
			status = "disabled";

			hsi2c_15: i2c@0 {
				compatible = "samsung,exynos8895-hsi2c";
				reg = <0x0 0x1000>;
				clocks = <&cmu_peric1 CLK_GOUT_PERIC1_USI05_I_PCLK>;
				clock-names = "hsi2c";
				interrupts = <GIC_SPI 394 IRQ_TYPE_LEVEL_HIGH>;
				pinctrl-0 = <&hsi2c15_bus>;
				pinctrl-names = "default";
				status = "disabled";
			};

			serial_7: serial@0 {
				compatible = "samsung,exynos8895-uart";
				reg = <0x0 0x100>;
				clocks = <&cmu_peric1 CLK_GOUT_PERIC1_USI05_I_PCLK>,
					 <&cmu_peric1 CLK_GOUT_PERIC1_USI05_I_SCLK_USI>;
				clock-names = "uart", "clk_uart_baud0";
				interrupts = <GIC_SPI 396 IRQ_TYPE_LEVEL_HIGH>;
				pinctrl-0 = <&uart7_bus>;
				pinctrl-names = "default";
				samsung,uart-fifosize = <64>;
				status = "disabled";
			};

			spi_7: spi@0 {
				compatible = "samsung,exynos8895-spi",
					     "samsung,exynos850-spi";
				reg = <0x0 0x100>;
				clocks = <&cmu_peric1 CLK_GOUT_PERIC1_USI05_I_PCLK>,
					 <&cmu_peric1 CLK_GOUT_PERIC1_USI05_I_SCLK_USI>;
				clock-names = "spi", "spi_busclk0";
				interrupts = <GIC_SPI 397 IRQ_TYPE_LEVEL_HIGH>;
				pinctrl-0 = <&spi7_bus>;
				pinctrl-names = "default";
				#address-cells = <1>;
				#size-cells = <0>;
				status = "disabled";
			};

			hsi2c_16: i2c@10000 {
				compatible = "samsung,exynos8895-hsi2c";
				reg = <0x10000 0x1000>;
				clocks = <&cmu_peric1 CLK_GOUT_PERIC1_USI05_I_PCLK>;
				clock-names = "hsi2c";
				interrupts = <GIC_SPI 395 IRQ_TYPE_LEVEL_HIGH>;
				pinctrl-0 = <&hsi2c16_bus>;
				pinctrl-names = "default";
				status = "disabled";
			};
		};

		usi6: usi@10880000 {
			compatible = "samsung,exynos8895-usi";
			ranges = <0x0 0x10880000 0x11000>;
			clocks = <&cmu_peric1 CLK_GOUT_PERIC1_USI06_I_PCLK>,
				 <&cmu_peric1 CLK_GOUT_PERIC1_USI06_I_SCLK_USI>;
			clock-names = "pclk", "ipclk";
			#address-cells = <1>;
			#size-cells = <1>;
			samsung,sysreg = <&syscon_peric1 0x1010>;
			status = "disabled";

			hsi2c_17: i2c@0 {
				compatible = "samsung,exynos8895-hsi2c";
				reg = <0x0 0x1000>;
				clocks = <&cmu_peric1 CLK_GOUT_PERIC1_USI06_I_PCLK>;
				clock-names = "hsi2c";
				interrupts = <GIC_SPI 398 IRQ_TYPE_LEVEL_HIGH>;
				pinctrl-0 = <&hsi2c17_bus>;
				pinctrl-names = "default";
				status = "disabled";
			};

			serial_8: serial@0 {
				compatible = "samsung,exynos8895-uart";
				reg = <0x0 0x100>;
				clocks = <&cmu_peric1 CLK_GOUT_PERIC1_USI06_I_PCLK>,
					 <&cmu_peric1 CLK_GOUT_PERIC1_USI06_I_SCLK_USI>;
				clock-names = "uart", "clk_uart_baud0";
				interrupts = <GIC_SPI 400 IRQ_TYPE_LEVEL_HIGH>;
				pinctrl-0 = <&uart8_bus>;
				pinctrl-names = "default";
				samsung,uart-fifosize = <64>;
				status = "disabled";
			};

			spi_8: spi@0 {
				compatible = "samsung,exynos8895-spi",
					     "samsung,exynos850-spi";
				reg = <0x0 0x100>;
				clocks = <&cmu_peric1 CLK_GOUT_PERIC1_USI06_I_PCLK>,
					 <&cmu_peric1 CLK_GOUT_PERIC1_USI06_I_SCLK_USI>;
				clock-names = "spi", "spi_busclk0";
				interrupts = <GIC_SPI 401 IRQ_TYPE_LEVEL_HIGH>;
				pinctrl-0 = <&spi8_bus>;
				pinctrl-names = "default";
				#address-cells = <1>;
				#size-cells = <0>;
				status = "disabled";
			};

			hsi2c_18: i2c@10000 {
				compatible = "samsung,exynos8895-hsi2c";
				reg = <0x10000 0x1000>;
				clocks = <&cmu_peric1 CLK_GOUT_PERIC1_USI06_I_PCLK>;
				clock-names = "hsi2c";
				interrupts = <GIC_SPI 399 IRQ_TYPE_LEVEL_HIGH>;
				pinctrl-0 = <&hsi2c18_bus>;
				pinctrl-names = "default";
				status = "disabled";
			};
		};

		usi7: usi@108a0000 {
			compatible = "samsung,exynos8895-usi";
			ranges = <0x0 0x108a0000 0x11000>;
			clocks = <&cmu_peric1 CLK_GOUT_PERIC1_USI07_I_PCLK>,
				 <&cmu_peric1 CLK_GOUT_PERIC1_USI07_I_SCLK_USI>;
			clock-names = "pclk", "ipclk";
			#address-cells = <1>;
			#size-cells = <1>;
			samsung,sysreg = <&syscon_peric1 0x1014>;
			status = "disabled";

			hsi2c_19: i2c@0 {
				compatible = "samsung,exynos8895-hsi2c";
				reg = <0x0 0x1000>;
				clocks = <&cmu_peric1 CLK_GOUT_PERIC1_USI07_I_PCLK>;
				clock-names = "hsi2c";
				interrupts = <GIC_SPI 402 IRQ_TYPE_LEVEL_HIGH>;
				pinctrl-0 = <&hsi2c19_bus>;
				pinctrl-names = "default";
				status = "disabled";
			};

			serial_9: serial@0 {
				compatible = "samsung,exynos8895-uart";
				reg = <0x0 0x100>;
				clocks = <&cmu_peric1 CLK_GOUT_PERIC1_USI07_I_PCLK>,
					 <&cmu_peric1 CLK_GOUT_PERIC1_USI07_I_SCLK_USI>;
				clock-names = "uart", "clk_uart_baud0";
				interrupts = <GIC_SPI 404 IRQ_TYPE_LEVEL_HIGH>;
				pinctrl-0 = <&uart9_bus>;
				pinctrl-names = "default";
				samsung,uart-fifosize = <64>;
				status = "disabled";
			};

			spi_9: spi@0 {
				compatible = "samsung,exynos8895-spi",
					     "samsung,exynos850-spi";
				reg = <0x0 0x100>;
				clocks = <&cmu_peric1 CLK_GOUT_PERIC1_USI07_I_PCLK>,
					 <&cmu_peric1 CLK_GOUT_PERIC1_USI07_I_SCLK_USI>;
				clock-names = "spi", "spi_busclk0";
				interrupts = <GIC_SPI 405 IRQ_TYPE_LEVEL_HIGH>;
				pinctrl-0 = <&spi9_bus>;
				pinctrl-names = "default";
				#address-cells = <1>;
				#size-cells = <0>;
				status = "disabled";
			};

			hsi2c_20: i2c@10000 {
				compatible = "samsung,exynos8895-hsi2c";
				reg = <0x10000 0x1000>;
				clocks = <&cmu_peric1 CLK_GOUT_PERIC1_USI07_I_PCLK>;
				clock-names = "hsi2c";
				interrupts = <GIC_SPI 403 IRQ_TYPE_LEVEL_HIGH>;
				pinctrl-0 = <&hsi2c20_bus>;
				pinctrl-names = "default";
				status = "disabled";
			};
		};

		usi8: usi@108c0000 {
			compatible = "samsung,exynos8895-usi";
			ranges = <0x0 0x108c0000 0x11000>;
			clocks = <&cmu_peric1 CLK_GOUT_PERIC1_USI08_I_PCLK>,
				 <&cmu_peric1 CLK_GOUT_PERIC1_USI08_I_SCLK_USI>;
			clock-names = "pclk", "ipclk";
			#address-cells = <1>;
			#size-cells = <1>;
			samsung,sysreg = <&syscon_peric1 0x1018>;
			status = "disabled";

			hsi2c_21: i2c@0 {
				compatible = "samsung,exynos8895-hsi2c";
				reg = <0x0 0x1000>;
				clocks = <&cmu_peric1 CLK_GOUT_PERIC1_USI08_I_PCLK>;
				clock-names = "hsi2c";
				interrupts = <GIC_SPI 406 IRQ_TYPE_LEVEL_HIGH>;
				pinctrl-0 = <&hsi2c21_bus>;
				pinctrl-names = "default";
				status = "disabled";
			};

			serial_10: serial@0 {
				compatible = "samsung,exynos8895-uart";
				reg = <0x0 0x100>;
				clocks = <&cmu_peric1 CLK_GOUT_PERIC1_USI08_I_PCLK>,
					 <&cmu_peric1 CLK_GOUT_PERIC1_USI08_I_SCLK_USI>;
				clock-names = "uart", "clk_uart_baud0";
				interrupts = <GIC_SPI 408 IRQ_TYPE_LEVEL_HIGH>;
				pinctrl-0 = <&uart10_bus>;
				pinctrl-names = "default";
				samsung,uart-fifosize = <64>;
				status = "disabled";
			};

			spi_10: spi@0 {
				compatible = "samsung,exynos8895-spi",
					     "samsung,exynos850-spi";
				reg = <0x0 0x100>;
				clocks = <&cmu_peric1 CLK_GOUT_PERIC1_USI08_I_PCLK>,
					 <&cmu_peric1 CLK_GOUT_PERIC1_USI08_I_SCLK_USI>;
				clock-names = "spi", "spi_busclk0";
				interrupts = <GIC_SPI 409 IRQ_TYPE_LEVEL_HIGH>;
				pinctrl-0 = <&spi10_bus>;
				pinctrl-names = "default";
				#address-cells = <1>;
				#size-cells = <0>;
				status = "disabled";
			};

			hsi2c_22: i2c@10000 {
				compatible = "samsung,exynos8895-hsi2c";
				reg = <0x10000 0x1000>;
				clocks = <&cmu_peric1 CLK_GOUT_PERIC1_USI08_I_PCLK>;
				clock-names = "hsi2c";
				interrupts = <GIC_SPI 407 IRQ_TYPE_LEVEL_HIGH>;
				pinctrl-0 = <&hsi2c22_bus>;
				pinctrl-names = "default";
				status = "disabled";
			};
		};

		usi9: usi@108e0000 {
			compatible = "samsung,exynos8895-usi";
			ranges = <0x0 0x108e0000 0x11000>;
			clocks = <&cmu_peric1 CLK_GOUT_PERIC1_USI09_I_PCLK>,
				 <&cmu_peric1 CLK_GOUT_PERIC1_USI09_I_SCLK_USI>;
			clock-names = "pclk", "ipclk";
			#address-cells = <1>;
			#size-cells = <1>;
			samsung,sysreg = <&syscon_peric1 0x101c>;
			status = "disabled";

			hsi2c_23: i2c@0 {
				compatible = "samsung,exynos8895-hsi2c";
				reg = <0x0 0x1000>;
				clocks = <&cmu_peric1 CLK_GOUT_PERIC1_USI09_I_PCLK>;
				clock-names = "hsi2c";
				interrupts = <GIC_SPI 410 IRQ_TYPE_LEVEL_HIGH>;
				pinctrl-0 = <&hsi2c23_bus>;
				pinctrl-names = "default";
				status = "disabled";
			};

			serial_11: serial@0 {
				compatible = "samsung,exynos8895-uart";
				reg = <0 0x100>;
				clocks = <&cmu_peric1 CLK_GOUT_PERIC1_USI09_I_PCLK>,
					 <&cmu_peric1 CLK_GOUT_PERIC1_USI09_I_SCLK_USI>;
				clock-names = "uart", "clk_uart_baud0";
				interrupts = <GIC_SPI 412 IRQ_TYPE_LEVEL_HIGH>;
				pinctrl-0 = <&uart11_bus>;
				pinctrl-names = "default";
				samsung,uart-fifosize = <64>;
				status = "disabled";
			};

			spi_11: spi@0 {
				compatible = "samsung,exynos8895-spi",
					     "samsung,exynos850-spi";
				reg = <0 0x100>;
				clocks = <&cmu_peric1 CLK_GOUT_PERIC1_USI09_I_PCLK>,
					 <&cmu_peric1 CLK_GOUT_PERIC1_USI09_I_SCLK_USI>;
				clock-names = "spi", "spi_busclk0";
				interrupts = <GIC_SPI 413 IRQ_TYPE_LEVEL_HIGH>;
				pinctrl-0 = <&spi11_bus>;
				pinctrl-names = "default";
				#address-cells = <1>;
				#size-cells = <0>;
				status = "disabled";
			};

			hsi2c_24: i2c@10000 {
				compatible = "samsung,exynos8895-hsi2c";
				reg = <0x10000 0x1000>;
				clocks = <&cmu_peric1 CLK_GOUT_PERIC1_USI09_I_PCLK>;
				clock-names = "hsi2c";
				interrupts = <GIC_SPI 411 IRQ_TYPE_LEVEL_HIGH>;
				pinctrl-0 = <&hsi2c24_bus>;
				pinctrl-names = "default";
				status = "disabled";
			};
		};

		usi10: usi@10900000 {
			compatible = "samsung,exynos8895-usi";
			ranges = <0x0 0x10900000 0x11000>;
			clocks = <&cmu_peric1 CLK_GOUT_PERIC1_USI10_I_PCLK>,
				 <&cmu_peric1 CLK_GOUT_PERIC1_USI10_I_SCLK_USI>;
			clock-names = "pclk", "ipclk";
			#address-cells = <1>;
			#size-cells = <1>;
			samsung,sysreg = <&syscon_peric1 0x1020>;
			status = "disabled";

			hsi2c_25: i2c@0 {
				compatible = "samsung,exynos8895-hsi2c";
				reg = <0x0 0x1000>;
				clocks = <&cmu_peric1 CLK_GOUT_PERIC1_USI10_I_PCLK>;
				clock-names = "hsi2c";
				interrupts = <GIC_SPI 414 IRQ_TYPE_LEVEL_HIGH>;
				pinctrl-0 = <&hsi2c25_bus>;
				pinctrl-names = "default";
				status = "disabled";
			};

			serial_12: serial@0 {
				compatible = "samsung,exynos8895-uart";
				reg = <0 0x100>;
				clocks = <&cmu_peric1 CLK_GOUT_PERIC1_USI10_I_PCLK>,
					 <&cmu_peric1 CLK_GOUT_PERIC1_USI10_I_SCLK_USI>;
				clock-names = "uart", "clk_uart_baud0";
				interrupts = <GIC_SPI 416 IRQ_TYPE_LEVEL_HIGH>;
				pinctrl-0 = <&uart12_bus>;
				pinctrl-names = "default";
				samsung,uart-fifosize = <64>;
				status = "disabled";
			};

			spi_12: spi@0 {
				compatible = "samsung,exynos8895-spi",
					     "samsung,exynos850-spi";
				reg = <0 0x100>;
				clocks = <&cmu_peric1 CLK_GOUT_PERIC1_USI10_I_PCLK>,
					 <&cmu_peric1 CLK_GOUT_PERIC1_USI10_I_SCLK_USI>;
				clock-names = "spi", "spi_busclk0";
				interrupts = <GIC_SPI 417 IRQ_TYPE_LEVEL_HIGH>;
				pinctrl-0 = <&spi12_bus>;
				pinctrl-names = "default";
				#address-cells = <1>;
				#size-cells = <0>;
				status = "disabled";
			};

			hsi2c_26: i2c@10000 {
				compatible = "samsung,exynos8895-hsi2c";
				reg = <0x10000 0x1000>;
				clocks = <&cmu_peric1 CLK_GOUT_PERIC1_USI10_I_PCLK>;
				clock-names = "hsi2c";
				interrupts = <GIC_SPI 415 IRQ_TYPE_LEVEL_HIGH>;
				pinctrl-0 = <&hsi2c26_bus>;
				pinctrl-names = "default";
				status = "disabled";
			};
		};

		usi11: usi@10920000 {
			compatible = "samsung,exynos8895-usi";
			ranges = <0x0 0x10920000 0x11000>;
			clocks = <&cmu_peric1 CLK_GOUT_PERIC1_USI11_I_PCLK>,
				 <&cmu_peric1 CLK_GOUT_PERIC1_USI11_I_SCLK_USI>;
			clock-names = "pclk", "ipclk";
			#address-cells = <1>;
			#size-cells = <1>;
			samsung,sysreg = <&syscon_peric1 0x1024>;
			status = "disabled";

			hsi2c_27: i2c@0 {
				compatible = "samsung,exynos8895-hsi2c";
				reg = <0x0 0x1000>;
				clocks = <&cmu_peric1 CLK_GOUT_PERIC1_USI11_I_PCLK>;
				clock-names = "hsi2c";
				interrupts = <GIC_SPI 418 IRQ_TYPE_LEVEL_HIGH>;
				pinctrl-0 = <&hsi2c27_bus>;
				pinctrl-names = "default";
				status = "disabled";
			};

			serial_13: serial@0 {
				compatible = "samsung,exynos8895-uart";
				reg = <0 0x100>;
				clocks = <&cmu_peric1 CLK_GOUT_PERIC1_USI11_I_PCLK>,
					 <&cmu_peric1 CLK_GOUT_PERIC1_USI11_I_SCLK_USI>;
				clock-names = "uart", "clk_uart_baud0";
				interrupts = <GIC_SPI 420 IRQ_TYPE_LEVEL_HIGH>;
				pinctrl-0 = <&uart13_bus>;
				pinctrl-names = "default";
				samsung,uart-fifosize = <64>;
				status = "disabled";
			};

			spi_13: spi@0 {
				compatible = "samsung,exynos8895-spi",
					     "samsung,exynos850-spi";
				reg = <0 0x100>;
				clocks = <&cmu_peric1 CLK_GOUT_PERIC1_USI11_I_PCLK>,
					 <&cmu_peric1 CLK_GOUT_PERIC1_USI11_I_SCLK_USI>;
				clock-names = "spi", "spi_busclk0";
				interrupts = <GIC_SPI 421 IRQ_TYPE_LEVEL_HIGH>;
				pinctrl-0 = <&spi13_bus>;
				pinctrl-names = "default";
				#address-cells = <1>;
				#size-cells = <0>;
				status = "disabled";
			};

			hsi2c_28: i2c@10000 {
				compatible = "samsung,exynos8895-hsi2c";
				reg = <0x10000 0x1000>;
				clocks = <&cmu_peric1 CLK_GOUT_PERIC1_USI11_I_PCLK>;
				clock-names = "hsi2c";
				interrupts = <GIC_SPI 419 IRQ_TYPE_LEVEL_HIGH>;
				pinctrl-0 = <&hsi2c28_bus>;
				pinctrl-names = "default";
				status = "disabled";
			};
		};

		usi12: usi@10940000 {
			compatible = "samsung,exynos8895-usi";
			ranges = <0x0 0x10940000 0x11000>;
			clocks = <&cmu_peric1 CLK_GOUT_PERIC1_USI12_I_PCLK>,
				 <&cmu_peric1 CLK_GOUT_PERIC1_USI12_I_SCLK_USI>;
			clock-names = "pclk", "ipclk";
			#address-cells = <1>;
			#size-cells = <1>;
			samsung,sysreg = <&syscon_peric1 0x1028>;
			status = "disabled";

			hsi2c_29: i2c@0 {
				compatible = "samsung,exynos8895-hsi2c";
				reg = <0x0 0x1000>;
				clocks = <&cmu_peric1 CLK_GOUT_PERIC1_USI12_I_PCLK>;
				clock-names = "hsi2c";
				interrupts = <GIC_SPI 422 IRQ_TYPE_LEVEL_HIGH>;
				pinctrl-0 = <&hsi2c29_bus>;
				pinctrl-names = "default";
				status = "disabled";
			};

			serial_14: serial@0 {
				compatible = "samsung,exynos8895-uart";
				reg = <0 0x100>;
				clocks = <&cmu_peric1 CLK_GOUT_PERIC1_USI12_I_PCLK>,
					 <&cmu_peric1 CLK_GOUT_PERIC1_USI12_I_SCLK_USI>;
				clock-names = "uart", "clk_uart_baud0";
				interrupts = <GIC_SPI 424 IRQ_TYPE_LEVEL_HIGH>;
				pinctrl-0 = <&uart14_bus>;
				pinctrl-names = "default";
				samsung,uart-fifosize = <64>;
				status = "disabled";
			};

			spi_14: spi@0 {
				compatible = "samsung,exynos8895-spi",
					     "samsung,exynos850-spi";
				reg = <0 0x100>;
				clocks = <&cmu_peric1 CLK_GOUT_PERIC1_USI12_I_PCLK>,
					 <&cmu_peric1 CLK_GOUT_PERIC1_USI12_I_SCLK_USI>;
				clock-names = "spi", "spi_busclk0";
				interrupts = <GIC_SPI 425 IRQ_TYPE_LEVEL_HIGH>;
				pinctrl-0 = <&spi14_bus>;
				pinctrl-names = "default";
				#address-cells = <1>;
				#size-cells = <0>;
				status = "disabled";
			};

			hsi2c_30: i2c@10000 {
				compatible = "samsung,exynos8895-hsi2c";
				reg = <0x10000 0x1000>;
				clocks = <&cmu_peric1 CLK_GOUT_PERIC1_USI12_I_PCLK>;
				clock-names = "hsi2c";
				interrupts = <GIC_SPI 423 IRQ_TYPE_LEVEL_HIGH>;
				pinctrl-0 = <&hsi2c30_bus>;
				pinctrl-names = "default";
				status = "disabled";
			};
		};

		usi13: usi@10960000 {
			compatible = "samsung,exynos8895-usi";
			ranges = <0x0 0x10960000 0x11000>;
			clocks = <&cmu_peric1 CLK_GOUT_PERIC1_USI13_I_PCLK>,
				 <&cmu_peric1 CLK_GOUT_PERIC1_USI13_I_SCLK_USI>;
			clock-names = "pclk", "ipclk";
			#address-cells = <1>;
			#size-cells = <1>;
			samsung,sysreg = <&syscon_peric1 0x102c>;
			status = "disabled";

			hsi2c_31: i2c@0 {
				compatible = "samsung,exynos8895-hsi2c";
				reg = <0x0 0x1000>;
				clocks = <&cmu_peric1 CLK_GOUT_PERIC1_USI13_I_PCLK>;
				clock-names = "hsi2c";
				interrupts = <GIC_SPI 426 IRQ_TYPE_LEVEL_HIGH>;
				pinctrl-0 = <&hsi2c31_bus>;
				pinctrl-names = "default";
				status = "disabled";
			};

			serial_15: serial@0 {
				compatible = "samsung,exynos8895-uart";
				reg = <0 0x100>;
				clocks = <&cmu_peric1 CLK_GOUT_PERIC1_USI13_I_PCLK>,
					 <&cmu_peric1 CLK_GOUT_PERIC1_USI13_I_SCLK_USI>;
				clock-names = "uart", "clk_uart_baud0";
				interrupts = <GIC_SPI 428 IRQ_TYPE_LEVEL_HIGH>;
				pinctrl-0 = <&uart15_bus>;
				pinctrl-names = "default";
				samsung,uart-fifosize = <64>;
				status = "disabled";
			};

			spi_15: spi@0 {
				compatible = "samsung,exynos8895-spi",
					     "samsung,exynos850-spi";
				reg = <0 0x100>;
				clocks = <&cmu_peric1 CLK_GOUT_PERIC1_USI13_I_PCLK>,
					 <&cmu_peric1 CLK_GOUT_PERIC1_USI13_I_SCLK_USI>;
				clock-names = "spi", "spi_busclk0";
				interrupts = <GIC_SPI 429 IRQ_TYPE_LEVEL_HIGH>;
				pinctrl-0 = <&spi15_bus>;
				pinctrl-names = "default";
				#address-cells = <1>;
				#size-cells = <0>;
				status = "disabled";
			};

			hsi2c_32: i2c@10000 {
				compatible = "samsung,exynos8895-hsi2c";
				reg = <0x10000 0x1000>;
				clocks = <&cmu_peric1 CLK_GOUT_PERIC1_USI13_I_PCLK>;
				clock-names = "hsi2c";
				interrupts = <GIC_SPI 427 IRQ_TYPE_LEVEL_HIGH>;
				pinctrl-0 = <&hsi2c32_bus>;
				pinctrl-names = "default";
				status = "disabled";
			};
		};

		pinctrl_peric1: pinctrl@10980000 {
			compatible = "samsung,exynos8895-pinctrl";
			reg = <0x10980000 0x1000>;
			interrupts = <GIC_SPI 430 IRQ_TYPE_LEVEL_HIGH>;
		};

		hsi2c_1: i2c@10990000 {
			compatible = "samsung,exynos8895-hsi2c";
			reg = <0x10990000 0x1000>;
			clocks = <&cmu_peric1 CLK_GOUT_PERIC1_HSI2C_CAM0_IPCLK>;
			clock-names = "hsi2c";
			interrupts = <GIC_SPI 431 IRQ_TYPE_LEVEL_HIGH>;
			pinctrl-0 = <&hsi2c1_bus>;
			pinctrl-names = "default";
			status = "disabled";
		};

		hsi2c_2: i2c@109a0000 {
			compatible = "samsung,exynos8895-hsi2c";
			reg = <0x109a0000 0x1000>;
			clocks = <&cmu_peric1 CLK_GOUT_PERIC1_HSI2C_CAM1_IPCLK>;
			clock-names = "hsi2c";
			interrupts = <GIC_SPI 432 IRQ_TYPE_LEVEL_HIGH>;
			pinctrl-0 = <&hsi2c2_bus>;
			pinctrl-names = "default";
			status = "disabled";
		};

		hsi2c_3: i2c@109b0000 {
			compatible = "samsung,exynos8895-hsi2c";
			reg = <0x109b0000 0x1000>;
			clocks = <&cmu_peric1 CLK_GOUT_PERIC1_HSI2C_CAM2_IPCLK>;
			clock-names = "hsi2c";
			interrupts = <GIC_SPI 433 IRQ_TYPE_LEVEL_HIGH>;
			pinctrl-0 = <&hsi2c3_bus>;
			pinctrl-names = "default";
			status = "disabled";
		};

		hsi2c_4: i2c@109c0000 {
			compatible = "samsung,exynos8895-hsi2c";
			reg = <0x109c0000 0x1000>;
			clocks = <&cmu_peric1 CLK_GOUT_PERIC1_HSI2C_CAM3_IPCLK>;
			clock-names = "hsi2c";
			interrupts = <GIC_SPI 434 IRQ_TYPE_LEVEL_HIGH>;
			pinctrl-0 = <&hsi2c4_bus>;
			pinctrl-names = "default";
			status = "disabled";
		};

		spi_0: spi@109d0000 {
			compatible = "samsung,exynos8895-spi",
				     "samsung,exynos850-spi";
			reg = <0x109d0000 0x100>;
			#address-cells = <1>;
			#size-cells = <0>;
			clocks = <&cmu_peric1 CLK_GOUT_PERIC1_SPI_CAM0_PCLK>,
				 <&cmu_peric1 CLK_GOUT_PERIC1_SPI_CAM0_SPI_EXT_CLK>;
			clock-names = "spi", "spi_busclk0";
			interrupts = <GIC_SPI 435 IRQ_TYPE_LEVEL_HIGH>;
			pinctrl-0 = <&spi0_bus>;
			pinctrl-names = "default";
			status = "disabled";
		};

		spi_1: spi@109e0000 {
			compatible = "samsung,exynos8895-spi",
				     "samsung,exynos850-spi";
			reg = <0x109e0000 0x100>;
			#address-cells = <1>;
			#size-cells = <0>;
			clocks = <&cmu_peric1 CLK_GOUT_PERIC1_SPI_CAM1_PCLK>,
				 <&cmu_peric1 CLK_GOUT_PERIC1_SPI_CAM1_SPI_EXT_CLK>;
			clock-names = "spi", "spi_busclk0";
			interrupts = <GIC_SPI 436 IRQ_TYPE_LEVEL_HIGH>;
			pinctrl-0 = <&spi1_bus>;
			pinctrl-names = "default";
			status = "disabled";
		};

		/*
		 * USB 3.0 DRD controller (L3 4.1): stock "samsung,exynos8895-dwusb3" at
		 * 0x10c00000 size 0x10000 (FDT:7854-7858). Stock "aclk" (FDT:7856-7857, the
		 * link Q-channel vclk 0x2ca) has no 6.18 clock; the link's AXI gate is
		 * held instead. Stock "sclk" (0x2bf, USBDRD30) = the REF_CLK gate. Stock
		 * enables the USBTV IP as one vclk that also holds the USBTVH AHB and
		 * core gates (S:drivers/soc/samsung/cal-if/exynos8895/cmucal-vclk.c:1442-1449);
		 * without a user, clk_disable_unused gates them and the core never binds.
		 */
		usbdrd: usb@10c00000 {
			compatible = "samsung,exynos8895-dwusb3";
			ranges = <0x0 0x10c00000 0x10000>;
			clocks = <&cmu_fsys0 CLK_GOUT_FSYS0_USBTV_I_USB30DRD_ACLK>,
				 <&cmu_fsys0 CLK_GOUT_FSYS0_USBTV_I_USB30DRD_REF_CLK>,
				 <&cmu_fsys0 CLK_GOUT_FSYS0_USBTV_I_USBTVH_AHB_CLK>,
				 <&cmu_fsys0 CLK_GOUT_FSYS0_USBTV_I_USBTVH_CORE_CLK>;
			clock-names = "aclk", "ref", "usbtvh_ahb", "usbtvh_core";
			#address-cells = <1>;
			#size-cells = <1>;
			status = "disabled";

			usbdrd_dwc3: usb@0 {
				compatible = "snps,dwc3";
				reg = <0x0 0x10000>;				/* FDT:7868 */
				interrupts = <GIC_SPI 337 IRQ_TYPE_LEVEL_HIGH>;	/* FDT:7869 <0 0x151 0> */
				/* GCTL.PWRDNSCALE; stock suspend_clk_freq 66 MHz, FDT:7871 */
				clocks = <&cmu_fsys0 CLK_GOUT_FSYS0_USBTV_I_USB30DRD_SUSPEND_CLK>;
				clock-names = "suspend";
				phys = <&usbdrd_phy 0>, <&usbdrd_phy 1>;	/* FDT:7873-7874 */
				phy-names = "usb2-phy", "usb3-phy";
				/* stock clears GUSB2PHYCFG SUSPHY and ENBLSLPM: S:drivers/usb/dwc3/core.c:714-715 */
				snps,dis_u2_susphy_quirk;
				snps,dis_enblslpm_quirk;
				/* no LPM, no U1/U2 (IKC:3598): S:drivers/usb/gadget/composite.c:611-612, S:drivers/usb/dwc3/ep0.c:633-652 */
				snps,usb2-gadget-lpm-disable;
				snps,dis-u1-entry-quirk;
				snps,dis-u2-entry-quirk;
				/*
				 * DWC_usb3 2.80a (GSNPSID 0x5533280a): stock sets
				 * GUSB3PIPECTL.DIS_RXDETP3 for >= 2.50a, S:drivers/usb/dwc3/core.c:162-166
				 */
				snps,dis_rxdet_inp3_quirk;
			};
		};

		/* USB 3.0 DRD PHY (L3 4.1): FDT:7880-7905 */
		usbdrd_phy: phy@10e00000 {
			compatible = "samsung,exynos8895-usbdrd-phy";
			reg = <0x10e00000 0x100>,	/* window 0, FDT:7882 */
			      <0x10e10000 0x100>,	/* window 1, FDT:7882 */
			      <0x10e50070 0x10>;	/* refclk select, FDT:7901 */
			clocks = <&cmu_fsys0 CLK_GOUT_FSYS0_USBTV_I_USB30DRD_ACLK>,
				 <&oscclk>;		/* stock ext_xtal = OSCCLK, FDT:7883 */
			clock-names = "phy", "ref";
			samsung,pmu-syscon = <&pmu_system_controller>;	/* FDT:7885 */
			#phy-cells = <1>;				/* FDT:7888 */
			status = "disabled";
		};

		cmu_fsys0: clock-controller@11000000 {
			compatible = "samsung,exynos8895-cmu-fsys0";
			reg = <0x11000000 0x8000>;
			#clock-cells = <1>;
			clocks = <&oscclk>,
				 <&cmu_top CLK_DOUT_CMU_FSYS0_BUS>,
				 <&cmu_top CLK_DOUT_CMU_FSYS0_DPGTC>,
				 <&cmu_top CLK_DOUT_CMU_FSYS0_MMC_EMBD>,
				 <&cmu_top CLK_DOUT_CMU_FSYS0_UFS_EMBD>,
				 <&cmu_top CLK_DOUT_CMU_FSYS0_USBDRD30>;
			clock-names = "oscclk", "bus", "dpgtc", "mmc",
				      "ufs", "usbdrd30";
		};

		syscon_fsys0: syscon@11020000 {
			compatible = "samsung,exynos8895-fsys0-sysreg", "syscon";
			reg = <0x11020000 0x2000>;
			clocks = <&cmu_fsys0 CLK_GOUT_FSYS0_SYSREG_FSYS0_PCLK>;
		};

		pinctrl_fsys0: pinctrl@11050000 {
			compatible = "samsung,exynos8895-pinctrl";
			reg = <0x11050000 0x1000>;
			interrupts = <GIC_SPI 335 IRQ_TYPE_LEVEL_HIGH>;
		};

		/*
		 * UFS 2.1 host, stock "hw-rev 4". Stock node:
		 * S:arch/arm64/boot/dts/exynos/exynos8895.dtsi:817-1100 (FDT:4693-4763).
		 * Clocks: the three FSYS0 IP gates of the UFS block (stock gate list
		 * CAL:cmucal-vclk.c:1437-1441); stock DT named the HWACG Q-channel
		 * GATE_UFS_EMBD and the TOP rate UFS_EMBD instead. The ufs-phy,
		 * ufs-io-coherency and ufs-tcxo-sel children become phys,
		 * samsung,sysreg and a driver constant into the same syscon.
		 */
		ufs: ufs@11120000 {
			compatible = "samsung,exynos8895-ufs";
			reg = <0x11120000 0x200>,	/* S:exynos8895.dtsi:827 "0: HCI standard" */
			      <0x11121100 0x200>,	/* :828 "1: Vendor specificed" */
			      <0x11110000 0x8000>,	/* :829 "2: UNIPRO" */
			      <0x11130000 0x100>;	/* :830 "3: UFS protector", mapped, never accessed */
			reg-names = "hci", "vs_hci", "unipro", "ufsp";
			interrupts = <GIC_SPI 334 IRQ_TYPE_LEVEL_HIGH>;	/* :831 "<0 334 0>" */
			clocks = <&cmu_fsys0 CLK_GOUT_FSYS0_UFS_EMBD_I_ACLK>,
				 <&cmu_fsys0 CLK_GOUT_FSYS0_UFS_EMBD_I_CLK_UNIPRO>,
				 <&cmu_fsys0 CLK_GOUT_FSYS0_UFS_EMBD_I_FMP_CLK>;
			clock-names = "core_clk", "sclk_unipro_main", "fmp";
			freq-table-hz = <0 0>, <0 0>, <0 0>;	/* :858 "<0 0>, <0 0>": no rate is set */
			pinctrl-names = "default";
			pinctrl-0 = <&ufs_rst_n &ufs_refclk_out>;	/* :833 */
			phys = <&ufs_phy>;
			phy-names = "ufs-phy";
			samsung,sysreg = <&syscon_fsys0 0x700>;	/* :1082-1086 0x11020700, bits 9:8 */
			dma-coherent;				/* :850 */
			status = "disabled";
		};

		/* Embedded UFS M-PHY: S:exynos8895.dtsi:1065-1074 (FDT:4735-4745) */
		ufs_phy: phy@11124000 {
			compatible = "samsung,exynos8895-ufs-phy";
			reg = <0x11124000 0x800>;	/* :1069 */
			reg-names = "phy-pma";
			clocks = <&oscclk>;		/* 26 MHz TCXO, "use alternative" path :1097-1098 */
			clock-names = "ref_clk";
			samsung,pmu-syscon = <&pmu_system_controller 0x724>;	/* ufs-phy-sys :1072 0x16480724 */
			#phy-cells = <0>;
			status = "disabled";
		};

		cmu_fsys1: clock-controller@11400000 {
			compatible = "samsung,exynos8895-cmu-fsys1";
			reg = <0x11400000 0x8000>;
			#clock-cells = <1>;
			clocks = <&oscclk>,
				 <&cmu_top CLK_DOUT_CMU_FSYS1_BUS>,
				 <&cmu_top CLK_DOUT_CMU_FSYS1_PCIE>,
				 <&cmu_top CLK_DOUT_CMU_FSYS1_UFS_CARD>,
				 <&cmu_top CLK_DOUT_CMU_FSYS1_MMC_CARD>;
			clock-names = "oscclk", "bus", "pcie", "ufs", "mmc";
		};

		syscon_fsys1: syscon@11420000 {
			compatible = "samsung,exynos8895-fsys1-sysreg", "syscon";
			reg = <0x11420000 0x2000>;
			clocks = <&cmu_fsys1 CLK_GOUT_FSYS1_SYSREG_FSYS1_PCLK>;
		};

		pinctrl_fsys1: pinctrl@11430000 {
			compatible = "samsung,exynos8895-pinctrl";
			reg = <0x11430000 0x1000>;
			interrupts = <GIC_SPI 342 IRQ_TYPE_LEVEL_HIGH>;
		};

		mmc: mmc@11500000 {
			/* no -smu: stock never programs the SD slot's SMU (cfg_smu only for
			 * mshc alias 0, S:drivers/mmc/host/dw_mmc-exynos.c:256-269; this is
			 * mshc2, S:arch/arm64/boot/dts/exynos/exynos8895.dtsi:143) */
			compatible = "samsung,exynos8895-dw-mshc",
				     "samsung,exynos7-dw-mshc";
			reg = <0x11500000 0x2000>;
			assigned-clocks = <&cmu_top CLK_MOUT_CMU_FSYS1_MMC_CARD>;
			/* stock MMC_CARD LUT: mux 1 = PLL_SHARED2 (800 MHz), div 0
			 * (CAL:cmucal-vclk.c:2580-2581, cmucal-vclklut.c:137-138,
			 * cmucal-node.c:20-21,275-278) */
			assigned-clock-parents = <&cmu_top CLK_FOUT_SHARED2_PLL>;
			clocks = <&cmu_fsys1 CLK_GOUT_FSYS1_MMC_CARD_I_ACLK>,
				 <&cmu_fsys1 CLK_GOUT_FSYS1_MMC_CARD_SDCLKIN>;
			clock-names = "biu", "ciu";
			fifo-depth = <64>;
			interrupts = <GIC_SPI 341 IRQ_TYPE_LEVEL_HIGH>;
			#address-cells = <1>;
			#size-cells = <0>;
			status = "disabled";
		};

		/* L6D PCIe RC0 (K-F3) */
		pcie0: pcie@11700000 {
			compatible = "samsung,exynos8895-pcie";
			reg = <0x11700000 0x1000>,	/* dbi    FDT:8220 (4th region) */
			      <0x116a0000 0x1000>,	/* elbi   FDT:8220 (1st) */
			      <0x116d0000 0x1000>,	/* phy    FDT:8220 (2nd); shared with ch1 FDT:8256 */
			      <0x116c0000 0x1fc>,	/* pcs    FDT:8220 (5th); shared with ch1 FDT:8256 */
			      <0x11bff000 0x1000>;	/* config FDT:8220 (6th) */
			reg-names = "dbi", "elbi", "phy", "pcs", "config";
			interrupts = <GIC_SPI 345 IRQ_TYPE_LEVEL_HIGH>;	/* FDT:8222 <0 0x159 0>; type as the stock interrupt-map FDT:8234 (4) */
			clocks = <&cmu_fsys1 CLK_GOUT_FSYS1_PCIE_DBI_ACLK_0>,
				 <&cmu_fsys1 CLK_GOUT_FSYS1_PCIE_MSTR_ACLK_0>,
				 <&cmu_fsys1 CLK_GOUT_FSYS1_PCIE_SLV_ACLK_0>,
				 <&cmu_fsys1 CLK_GOUT_FSYS1_PCIE_PCIE_SUB_CTRL_INST_0_I_DRIVER_APB_CLK>,
				 <&cmu_fsys1 CLK_GOUT_FSYS1_PCIE_PIPE2_DIGITAL_X2_WRAP_INST_0_I_APB_PCLK_SCL>,
				 <&cmu_fsys1 CLK_GOUT_FSYS1_PCIE_IEEE1500_WRAPPER_FOR_PCIE_PHY_LC_X2_INST_0_I_SCL_APB_PCLK>,
				 <&cmu_fsys1 CLK_GOUT_FSYS1_PCIE_PHY_REF_CLK_IN>,
				 <&cmu_fsys1 CLK_GOUT_FSYS1_PCIE_DBI_ACLK_1>,
				 <&cmu_fsys1 CLK_GOUT_FSYS1_PCIE_MSTR_ACLK_1>,
				 <&cmu_fsys1 CLK_GOUT_FSYS1_PCIE_SLV_ACLK_1>,
				 <&cmu_fsys1 CLK_GOUT_FSYS1_PCIE_PCIE_SUB_CTRL_INST_1_I_DRIVER_APB_CLK>,
				 <&cmu_fsys1 CLK_GOUT_FSYS1_TOE_WIFI0_I_CLK>,
				 <&cmu_fsys1 CLK_GOUT_FSYS1_TOE_WIFI1_I_CLK>;
			clock-names = "dbi", "mstr", "slv", "apb", "pipe_apb", "phy_apb", "ref",
				      "dbi1", "mstr1", "slv1", "apb1", "toe0", "toe1";
			/* The six after "ref" (hardware test, image 0063/0064): stock booted with clk_ignore_unused
			 * (FDT:11147 bootargs), so no FSYS1 PCIe/TOE gate was ever turned off. Unclaimed, ACK's
			 * clk_disable_unused stops them after this probe and the next ELBI read (exynos_pcie_poweron,
			 * PCIE_STATE_HISTORY_CHECK) takes a synchronous external abort. Channel 1 shares the PHY and
			 * sub-controller with channel 0 (FDT:8220/8256); held here, they keep the stock state. */
			/* stock claims none (FDT:8239-8240, HWACG Q-channel gates S:drivers/clk/samsung/clk-exynos8895.c:236-245);
			 * ACK gates are manual, class IP (L1_platform.md:484) -> held here; ids/offsets RL-5 */
			samsung,pmu-syscon = <&pmu_system_controller>;	/* FDT:8223 samsung,syscon-phandle = <0x1f> (PMU); 0x610, 0x71C */
			samsung,fsys-sysreg = <&syscon_fsys1 0x1044>;	/* FDT:8220 "sysreg" 0x11421044 = syscon_fsys1 0x11420000 + 0x1044; FDT:8224 */
			#address-cells = <3>;			/* FDT:8228 */
			#size-cells = <2>;			/* FDT:8229 */
			device_type = "pci";			/* FDT:8230 */
			ranges = <0x82000000 0x0 0x11800000 0x11800000 0x0 0x400000>;	/* FDT:8231 (parent address = 1 cell here) */
			bus-range = <0x00 0xff>;		/* stock dw_pcie 4.4 root bus 0 (pci-exynos.c:1051); secondary 1 */
			#interrupt-cells = <1>;			/* FDT:8232 */
			interrupt-map-mask = <0 0 0 0>;		/* FDT:8233 */
			interrupt-map = <0 0 0 0 &gic GIC_SPI 345 IRQ_TYPE_LEVEL_HIGH>;	/* FDT:8234 <.. 0x01 0x00 0x159 0x04> */
			num-lanes = <1>;			/* FDT:8236 */
			status = "disabled";
		};

		cmu_dpu0: clock-controller@12800000 {
			compatible = "samsung,exynos8895-cmu-dpu0";
			reg = <0x12800000 0x8000>;	/* CAL:cmucal-sfr.c:19 SFR_BLOCK(DPU0, 0x12800000, 0x8000) */
			#clock-cells = <1>;
			clocks = <&oscclk>,
				 <&cmu_top CLK_DOUT_CMU_DPU_BUS>;	/* CAL:cmucal-node.c:1006 MUX_CLKCMU_DPU_BUS_USER parents */
			clock-names = "oscclk", "bus";
			power-domains = <&pd_dpu0>;	/* CAL:pmucal_local_exynos8895.h:203-232 dpu0_save */
			status = "disabled";
		};

		/*
		 * SYSREG_DPU0 (S:drivers/video/fbdev/exynos/dpu/regs-decon.h:69): DISP_SS
		 * LPMUX/DLMUX/MIPI_PHY_CON/TE_SEL at +0x1000..+0x100c (vendor mapping
		 * FDT:7465 <0x12821000 0x10>, regs-decon.h:21,27,43,50) and
		 * BUS_COMPONENT_DRCG_EN at +0x200 (S:.../pmucal_local_exynos8895.h:230).
		 */
		syscon_dpu0: syscon@12820000 {
			compatible = "samsung,exynos8895-dpu0-sysreg", "syscon";
			reg = <0x12820000 0x2000>;
			clocks = <&cmu_dpu0 CLK_GOUT_DPU0_SYSREG_DPU0_PCLK>;	/* CAL:cmucal-sfr.c:978 (0x2108) */
		};

		/*
		 * DECON0 ("decon_f", FDT:7527-7558) with the DPP registers of its six
		 * channels (G0 G1 VG0 VG1 VGF0 VGF1 at 0x1000 each, FDT:7385..7440
		 * reg[0]) and DPU_DMA (common 0x0-0xff, channel n at n * 0x1000,
		 * FDT reg[1]/reg[2]): the vendor's seven "dpp" devices are part of
		 * this one device, the only master of the display System MMUs.
		 * Interrupts: frame start/done and extra by the vendor's index
		 * (S:drivers/video/fbdev/exynos/dpu/decon_dsi.c:151-214), then each
		 * channel's DMA and DPP interrupts (vendor order, S:.../dpu/
		 * dpp_drv.c:1033-1065).
		 * Clocks: the CMU_DPU0 gates of DECON0 (0x207c), DPP G0 (0x2080),
		 * DPU_DMA SFR (0x209c) and DMA channel 1 = G0/VG0 (0x2090,
		 * S:.../dpu/helper.c:593-597).
		 */
		decon: display-controller@12860000 {
			compatible = "samsung,exynos8895-decon";
			reg = <0x12860000 0x10000>,	/* FDT:7530; DSC0/1 at +0x4000/+0x5000 */
			      <0x12851000 0x6000>,
			      <0x128b0000 0x7000>;
			reg-names = "decon", "dpp", "dma";
			interrupts = <GIC_SPI 143 IRQ_TYPE_LEVEL_HIGH>,	/* FDT:7531 0x8f */
				     <GIC_SPI 144 IRQ_TYPE_LEVEL_HIGH>,	/* 0x90 */
				     <GIC_SPI 149 IRQ_TYPE_LEVEL_HIGH>,	/* 0x95 */
				     <GIC_SPI 183 IRQ_TYPE_LEVEL_HIGH>,	/* G0 FDT:7386 0xb7 */
				     <GIC_SPI 179 IRQ_TYPE_LEVEL_HIGH>,	/* 0xb3 */
				     <GIC_SPI 184 IRQ_TYPE_LEVEL_HIGH>,	/* G1 FDT:7397 0xb8 */
				     <GIC_SPI 181 IRQ_TYPE_LEVEL_HIGH>,	/* 0xb5 */
				     <GIC_SPI 185 IRQ_TYPE_LEVEL_HIGH>,	/* VG0 FDT:7408 0xb9 */
				     <GIC_SPI 180 IRQ_TYPE_LEVEL_HIGH>,	/* 0xb4 */
				     <GIC_SPI 186 IRQ_TYPE_LEVEL_HIGH>,	/* VG1 FDT:7419 0xba */
				     <GIC_SPI 182 IRQ_TYPE_LEVEL_HIGH>,	/* 0xb6 */
				     <GIC_SPI 188 IRQ_TYPE_LEVEL_HIGH>,	/* VGF0 FDT:7430 0xbc */
				     <GIC_SPI 177 IRQ_TYPE_LEVEL_HIGH>,	/* 0xb1 */
				     <GIC_SPI 187 IRQ_TYPE_LEVEL_HIGH>,	/* VGF1 FDT:7441 0xbb */
				     <GIC_SPI 178 IRQ_TYPE_LEVEL_HIGH>;	/* 0xb2 */
			interrupt-names = "frame_start", "frame_done", "extra",
					  "g0_dma", "g0_dpp", "g1_dma", "g1_dpp",
					  "vg0_dma", "vg0_dpp", "vg1_dma", "vg1_dpp",
					  "vgf0_dma", "vgf0_dpp", "vgf1_dma", "vgf1_dpp";
			clocks = <&cmu_dpu0 CLK_GOUT_DPU0_DECON0_ACLK>,	/* CAL:cmucal-sfr.c:971 */
				 <&cmu_dpu0 CLK_GOUT_DPU0_DPP_DPP_G0_ACLK>,	/* :1001 */
				 <&cmu_dpu0 CLK_GOUT_DPU0_DPU_DMA_ACLK_SFR>,	/* :1010 */
				 <&cmu_dpu0 CLK_GOUT_DPU0_DPU_DMA_ACLK_CH1>;	/* :1006 */
			clock-names = "aclk", "dpp_g0", "dma_sfr", "dma_ch1";
			power-domains = <&pd_dpu0>;	/* FDT:7537 */
			iommus = <&sysmmu_dpu0>, <&sysmmu_dpu1>, <&sysmmu_dpu2>;
			samsung,disp-sysreg = <&syscon_dpu0>;
			status = "disabled";

			ports {
				#address-cells = <1>;
				#size-cells = <0>;

				port@0 {
					reg = <0>;

					decon_to_dsi: endpoint {
						remote-endpoint = <&dsi_from_decon>;
					};
				};
			};
		};

		/*
		 * DSIM0 (FDT:7483-7492): APB gate in CMU_DPU0, D-PHY = DSIM0 of the
		 * PMU's MIPI PHY, pd_dpu1. PLL input 26 MHz (the vendor's fixed
		 * fin, S:.../dpu/dsim_reg.c:1459). The panel-side link values and
		 * port@1 come from the board.
		 */
		dsi: dsi@12870000 {
			compatible = "samsung,exynos8895-mipi-dsi";
			reg = <0x12870000 0x100>;	/* FDT:7485 */
			interrupts = <GIC_SPI 150 IRQ_TYPE_LEVEL_HIGH>;	/* FDT:7486 0x96 */
			clocks = <&cmu_dpu0 CLK_GOUT_DPU0_AD_APB_MIPI_DSIM0_PCLKS>;	/* CAL:cmucal-sfr.c:994 */
			clock-names = "bus";
			phys = <&mipi_phy 1>;	/* EXYNOS_MIPI_PHY_ID_DSIM0 */
			phy-names = "dsim";
			power-domains = <&pd_dpu1>;	/* FDT:7489 */
			samsung,pll-clock-frequency = <26000000>;
			samsung,disp-sysreg = <&syscon_dpu0>;
			samsung,dpu1-sysreg = <&syscon_dpu1>;
			#address-cells = <1>;
			#size-cells = <0>;
			status = "disabled";

			ports {
				#address-cells = <1>;
				#size-cells = <0>;

				port@0 {
					reg = <0>;

					dsi_from_decon: endpoint {
						remote-endpoint = <&decon_to_dsi>;
					};
				};
			};
		};

		/*
		 * Display System MMUs (FDT:7334-7380). Each serves several DPP
		 * channels of DECON0; the DECON is their only master (one master
		 * per System MMU). The second vendor interrupt is the secure one.
		 * Vendor-only properties dropped: qos (ACK writes QoS 15 itself),
		 * port-name, sysmmu,secure-*, sysmmu,tlb_property (no ACK consumer).
		 * power-domains: the vendor nodes have none (its bus-wide runtime
		 * PM powers them with the master); ACK needs it so no register is
		 * read with pd_dpu0 off. aclk/pclk: CMU_DPU0 gates.
		 */
		sysmmu_dpu0: iommu@12900000 {
			compatible = "samsung,exynos-sysmmu";
			reg = <0x12900000 0x3000>;	/* FDT:7336 */
			interrupts = <GIC_SPI 152 IRQ_TYPE_LEVEL_HIGH>;	/* FDT:7337 0x98 */
			clocks = <&cmu_dpu0 CLK_GOUT_DPU0_SYSMMU_DPUD0_ACLK>,	/* CAL:cmucal-sfr.c:983 */
				 <&cmu_dpu0 CLK_GOUT_DPU0_SYSMMU_DPUD0_PCLK_NONSECURE>;	/* :982 */
			clock-names = "aclk", "pclk";
			power-domains = <&pd_dpu0>;
			#iommu-cells = <0>;
			status = "disabled";
		};

		sysmmu_dpu1: iommu@12910000 {
			compatible = "samsung,exynos-sysmmu";
			reg = <0x12910000 0x3000>;	/* FDT:7352 */
			interrupts = <GIC_SPI 155 IRQ_TYPE_LEVEL_HIGH>;	/* FDT:7353 0x9b */
			clocks = <&cmu_dpu0 CLK_GOUT_DPU0_SYSMMU_DPUD1_ACLK>,	/* CAL:cmucal-sfr.c:1024 */
				 <&cmu_dpu0 CLK_GOUT_DPU0_SYSMMU_DPUD1_PCLK_NONSECURE>;	/* :985 */
			clock-names = "aclk", "pclk";
			power-domains = <&pd_dpu0>;
			#iommu-cells = <0>;
			status = "disabled";
		};

		sysmmu_dpu2: iommu@12920000 {
			compatible = "samsung,exynos-sysmmu";
			reg = <0x12920000 0x3000>;	/* FDT:7368 */
			interrupts = <GIC_SPI 158 IRQ_TYPE_LEVEL_HIGH>;	/* FDT:7369 0x9e */
			clocks = <&cmu_dpu0 CLK_GOUT_DPU0_SYSMMU_DPUD2_ACLK>,	/* CAL:cmucal-sfr.c:1015 */
				 <&cmu_dpu0 CLK_GOUT_DPU0_SYSMMU_DPUD2_PCLK_NONSECURE>;	/* :1017 */
			clock-names = "aclk", "pclk";
			power-domains = <&pd_dpu0>;
			#iommu-cells = <0>;
			status = "disabled";
		};

		cmu_dpu1: clock-controller@12a00000 {
			compatible = "samsung,exynos8895-cmu-dpu1";
			reg = <0x12a00000 0x8000>;	/* CAL:cmucal-sfr.c:20 SFR_BLOCK(DPU1, 0x12a00000, 0x8000) */
			#clock-cells = <1>;
			clocks = <&oscclk>,
				 <&cmu_dpu0 CLK_GOUT_DPU0_CLKCMU_DPU1_BUSD>,	/* CAL:cmucal-node.c:1007 { OSCCLK_DPU1, CLKCMU_DPU1_BUSD } */
				 <&cmu_dpu0 CLK_GOUT_DPU0_CLKCMU_DPU1_BUSP>;	/* CAL:cmucal-node.c:1008 { OSCCLK_DPU1, CLKCMU_DPU1_BUSP } */
			clock-names = "oscclk", "busd", "busp";
			power-domains = <&pd_dpu1>;	/* CAL:pmucal_local_exynos8895.h:247-269 dpu1_save */
			status = "disabled";
		};

		/*
		 * SYSREG_DPU1: only BUS_COMPONENT_DRCG_EN at +0x200 is used
		 * (S:.../pmucal_local_exynos8895.h:267). Its PCLK gate is in CMU_DPU1
		 * (CAL:cmucal-sfr.c:1064), which is not registered: no clocks.
		 */
		syscon_dpu1: syscon@12a20000 {
			compatible = "samsung,exynos8895-dpu1-sysreg", "syscon";
			reg = <0x12a20000 0x1000>;
		};

		cmu_cam: clock-controller@12c00000 {
			compatible = "samsung,exynos8895-cmu-cam";
			reg = <0x12c00000 0x8000>;	/* CAL:cmucal-sfr.c:12 SFR_BLOCK(CAM, 0x12c00000, 0x8000) */
			#clock-cells = <1>;
			clocks = <&oscclk>,
				 <&cmu_top CLK_DOUT_CMU_CAM_BUS>,	/* CAL:cmucal-node.c:597 */
				 <&cmu_top CLK_DOUT_CMU_CAM_TPU0>,	/* CAL:cmucal-node.c:601 */
				 <&cmu_top CLK_DOUT_CMU_CAM_TPU1>,	/* CAL:cmucal-node.c:609 */
				 <&cmu_top CLK_DOUT_CMU_CAM_VRA>;	/* CAL:cmucal-node.c:605 */
			clock-names = "oscclk", "bus", "tpu0", "tpu1", "vra";
			assigned-clocks = <&cmu_cam CLK_MOUT_CAM_BUS_USER>, <&cmu_cam CLK_MOUT_CAM_TPU0_USER>,
					  <&cmu_cam CLK_MOUT_CAM_TPU1_USER>, <&cmu_cam CLK_MOUT_CAM_VRA_USER>;
			assigned-clock-parents = <&cmu_top CLK_DOUT_CMU_CAM_BUS>, <&cmu_top CLK_DOUT_CMU_CAM_TPU0>,
						 <&cmu_top CLK_DOUT_CMU_CAM_TPU1>, <&cmu_top CLK_DOUT_CMU_CAM_VRA>;
			power-domains = <&pd_cam>;	/* CAL:pmucal_local_exynos8895.h:76-112 cam_save */
			status = "disabled";
		};

		cmu_dcam: clock-controller@12e00000 {
			compatible = "samsung,exynos8895-cmu-dcam";
			reg = <0x12e00000 0x8000>;	/* CAL:cmucal-sfr.c:18 SFR_BLOCK(DCAM, 0x12e00000, 0x8000) */
			#clock-cells = <1>;
			clocks = <&oscclk>,
				 <&cmu_top CLK_DOUT_CMU_DCAM_BUS>,	/* CAL:cmucal-node.c:633 */
				 <&cmu_top CLK_DOUT_CMU_DCAM_IMGD>;	/* CAL:cmucal-node.c:637 */
			clock-names = "oscclk", "bus", "imgd";
			assigned-clocks = <&cmu_dcam CLK_MOUT_DCAM_BUS_USER>, <&cmu_dcam CLK_MOUT_DCAM_IMGD_USER>;
			assigned-clock-parents = <&cmu_top CLK_DOUT_CMU_DCAM_BUS>, <&cmu_top CLK_DOUT_CMU_DCAM_IMGD>;
			power-domains = <&pd_dcam>;	/* CAL:pmucal_local_exynos8895.h:172-187 dcam_save */
			status = "disabled";
		};

		cmu_isplp: clock-controller@13000000 {
			compatible = "samsung,exynos8895-cmu-isplp";
			reg = <0x13000000 0x8000>;	/* CAL:cmucal-sfr.c:28 SFR_BLOCK(ISPLP, 0x13000000, 0x8000) */
			#clock-cells = <1>;
			clocks = <&oscclk>,
				 <&cmu_top CLK_DOUT_CMU_ISPLP_BUS>;	/* CAL:cmucal-node.c:713 */
			clock-names = "oscclk", "bus";
			assigned-clocks = <&cmu_isplp CLK_MOUT_ISPLP_BUS_USER>;
			assigned-clock-parents = <&cmu_top CLK_DOUT_CMU_ISPLP_BUS>;
			power-domains = <&pd_isplp>;	/* CAL:pmucal_local_exynos8895.h:416-435 isplp_save */
			status = "disabled";
		};

		cmu_isphq: clock-controller@13100000 {
			compatible = "samsung,exynos8895-cmu-isphq";
			reg = <0x13100000 0x8000>;	/* CAL:cmucal-sfr.c:27 SFR_BLOCK(ISPHQ, 0x13100000, 0x8000) */
			#clock-cells = <1>;
			clocks = <&oscclk>,
				 <&cmu_top CLK_DOUT_CMU_ISPHQ_BUS>;	/* CAL:cmucal-node.c:709 */
			clock-names = "oscclk", "bus";
			assigned-clocks = <&cmu_isphq CLK_MOUT_ISPHQ_BUS_USER>;
			assigned-clock-parents = <&cmu_top CLK_DOUT_CMU_ISPHQ_BUS>;
			power-domains = <&pd_isphq>;	/* CAL:pmucal_local_exynos8895.h:385-400 isphq_save */
			status = "disabled";
		};

		cmu_g3d: clock-controller@13800000 {
			compatible = "samsung,exynos8895-cmu-g3d";
			reg = <0x13800000 0x8000>;	/* CAL:cmucal-sfr.c:25 SFR_BLOCK(G3D, 0x13800000, 0x8000) */
			#clock-cells = <1>;
			clocks = <&oscclk>,
				 <&cmu_top CLK_DOUT_CMU_G3D_SWITCH>,	/* CAL:cmucal-node.c:701 { OSCCLK_G3D, CLKCMU_G3D_SWITCH } */
				 <&cmu_top CLK_DOUT_CMU_HPM>;	/* CAL:cmucal-node.c:1864 parent CLKCMU_HPM */
			clock-names = "oscclk", "switch", "hpm";
			status = "disabled";
		};

		/* L6A slice gpu: Mali-G71 MP20 for the vendor kbase r16p0 (spec L6A_graphics.md 4.1) */
		gpu: gpu@13900000 {
			/*
			 * Stock "arm,mali" (FDT:4637); not "arm,mali-bifrost", whose
			 * lower-case interrupt names (Documentation/devicetree/bindings/gpu/arm,mali-bifrost.yaml)
			 * this driver does not use.
			 */
			compatible = "samsung,exynos8895-mali";
			reg = <0x13900000 0x5000>;	/* FDT:4638 <0x00 0x13900000 0x5000> */
			interrupts = <GIC_SPI 60 IRQ_TYPE_LEVEL_HIGH>,	/* FDT:4639 <0x00 0x3c 0x00> JOB */
				     <GIC_SPI 61 IRQ_TYPE_LEVEL_HIGH>,	/* <0x00 0x3d 0x00> MMU */
				     <GIC_SPI 59 IRQ_TYPE_LEVEL_HIGH>;	/* <0x00 0x3b 0x00> GPU */
			interrupt-names = "JOB", "MMU", "GPU";	/* FDT:4640 */
			power-domains = <&pd_g3d>;	/* FDT:4642 samsung,power-domain = <0x18> */
			/* FDT:4641 g3d_cmu_cal_id = <0xb040004>, ACPM index 0xb040004 & 0xffff */
			clocks = <&acpm_ipc EXYNOS8895_CLK_ACPM_DVFS_G3D>;
			clock-names = "clk_mali";
			operating-points-v2 = <&gpu_opp_table>;
			#cooling-cells = <2>;		/* FDT:4644 */
			samsung,autosuspend-delay-ms = <50>;	/* FDT:4672 gpu_runtime_pm_delay_time = <0x32> */
			status = "disabled";
		};

		/*
		 * FDT:4648 gpu_dvfs_table column 0 inside [gpu_min_clock FDT:4655
		 * 0x3f7a0, gpu_max_clock FDT:4653 0x854d0]; each is also an ECT
		 * dvfs_g3d level (SB+0x4647c). No opp-microvolt: the APM owns the
		 * G3D voltage.
		 */
		gpu_opp_table: opp-table-gpu {
			compatible = "operating-points-v2";

			opp-260000000 {
				opp-hz = /bits/ 64 <260000000>;	/* 0x3f7a0 */
			};
			opp-338000000 {
				opp-hz = /bits/ 64 <338000000>;	/* 0x52850 */
			};
			opp-385000000 {
				opp-hz = /bits/ 64 <385000000>;	/* 0x5dfe8 */
			};
			opp-455000000 {
				opp-hz = /bits/ 64 <455000000>;	/* 0x6f158 */
			};
			opp-546000000 {
				opp-hz = /bits/ 64 <546000000>;	/* 0x854d0 */
			};
		};

		cmu_g2d: clock-controller@13a00000 {
			compatible = "samsung,exynos8895-cmu-g2d";
			reg = <0x13a00000 0x8000>;	/* CAL:cmucal-sfr.c:24 SFR_BLOCK(G2D, 0x13a00000, 0x8000) */
			#clock-cells = <1>;
			clocks = <&oscclk>,
				 <&cmu_top CLK_DOUT_CMU_G2D_G2D>,	/* CAL:cmucal-node.c:693 */
				 <&cmu_top CLK_DOUT_CMU_G2D_JPEG>;	/* CAL:cmucal-node.c:697 */
			clock-names = "oscclk", "g2d", "jpeg";
			assigned-clocks = <&cmu_g2d CLK_MOUT_G2D_G2D_USER>, <&cmu_g2d CLK_MOUT_G2D_JPEG_USER>;
			assigned-clock-parents = <&cmu_top CLK_DOUT_CMU_G2D_G2D>, <&cmu_top CLK_DOUT_CMU_G2D_JPEG>;
			power-domains = <&pd_g2d>;	/* CAL:pmucal_local_exynos8895.h:319-346 g2d_save */
			status = "disabled";
		};

		cmu_mfc: clock-controller@13c00000 {
			compatible = "samsung,exynos8895-cmu-mfc";
			reg = <0x13c00000 0x8000>;	/* CAL:cmucal-sfr.c:30 SFR_BLOCK(MFC, 0x13c00000, 0x8000) */
			#clock-cells = <1>;
			clocks = <&oscclk>,
				 <&cmu_top CLK_DOUT_CMU_MFC_BUS>;	/* CAL:cmucal-node.c:721 { OSCCLK_MFC, CLKCMU_MFC_BUS } */
			clock-names = "oscclk", "bus";
			assigned-clocks = <&cmu_mfc CLK_MOUT_MFC_BUS_USER>;
			assigned-clock-parents = <&cmu_top CLK_DOUT_CMU_MFC_BUS>;	/* UMUX := CLKCMU_MFC_BUS, stock ra.c:593-595 */
			power-domains = <&pd_mfc>;	/* CAL:pmucal_local_exynos8895.h:502-520 mfc_save */
			status = "disabled";
		};

		cmu_abox: clock-controller@13e00000 {
			compatible = "samsung,exynos8895-cmu-abox";
			reg = <0x13e00000 0x8000>;	/* CAL:cmucal-sfr.c:8 SFR_BLOCK(ABOX, 0x13e00000, 0x8000) */
			#clock-cells = <1>;
			clocks = <&oscclk>,	/* OSCCLK_ABOX 26 MHz, CAL:cmucal-node.c:2237 */
				 <&cmu_top CLK_DOUT_CMU_ABOX_CPUABOX>;	/* CAL:cmucal-node.c:577-579 CPUABOX_USER parents */
			clock-names = "oscclk", "cpuabox";
			power-domains = <&pd_abox>;	/* CAL:pmucal_local_exynos8895.h:6-59 abox_save */
			status = "disabled";
		};

		pinctrl_abox: pinctrl@13e60000 {
			compatible = "samsung,exynos8895-pinctrl";
			reg = <0x13e60000 0x1000>;
		};

		cmu_vts: clock-controller@14000000 {
			compatible = "samsung,exynos8895-cmu-vts";
			reg = <0x14000000 0x8000>;	/* CAL:cmucal-sfr.c:40 SFR_BLOCK(VTS, 0x14000000, 0x8000) */
			#clock-cells = <1>;
			clocks = <&oscclk>;	/* OSCCLK_VTS 26 MHz, CAL:cmucal-node.c:2286 */
			clock-names = "oscclk";
			power-domains = <&pd_vts>;	/* CAL:pmucal_local_exynos8895.h:603-634 vts_save */
			status = "disabled";
		};

		pinctrl_vts: pinctrl@14080000 {
			compatible = "samsung,exynos8895-pinctrl";
			reg = <0x14080000 0x1000>;
		};

		cmu_srdz: clock-controller@14200000 {
			compatible = "samsung,exynos8895-cmu-srdz";
			reg = <0x14200000 0x8000>;	/* CAL:cmucal-sfr.c:38 SFR_BLOCK(SRDZ, 0x14200000, 0x8000) */
			#clock-cells = <1>;
			clocks = <&oscclk>,
				 <&cmu_top CLK_DOUT_CMU_SRDZ_BUS>,	/* CAL:cmucal-node.c:817 */
				 <&cmu_top CLK_DOUT_CMU_SRDZ_IMGD>;	/* CAL:cmucal-node.c:813 */
			clock-names = "oscclk", "bus", "imgd";
			assigned-clocks = <&cmu_srdz CLK_MOUT_SRDZ_BUS_USER>, <&cmu_srdz CLK_MOUT_SRDZ_IMGD_USER>;
			assigned-clock-parents = <&cmu_top CLK_DOUT_CMU_SRDZ_BUS>, <&cmu_top CLK_DOUT_CMU_SRDZ_IMGD>;
			power-domains = <&pd_srdz>;	/* CAL:pmucal_local_exynos8895.h:536-555 srdz_save */
			status = "disabled";
		};

		cmu_busc: clock-controller@15a00000 {
			compatible = "samsung,exynos8895-cmu-busc";
			reg = <0x15a00000 0x8000>;	/* CAL:cmucal-sfr.c:11 SFR_BLOCK(BUSC, 0x15a00000, 0x8000) */
			#clock-cells = <1>;
			clocks = <&oscclk>,
				 <&cmu_top CLK_DOUT_CMU_BUSC_BUS>,	/* CAL:cmucal-node.c:589 { OSCCLK_BUSC, CLKCMU_BUSC_BUS } */
				 <&cmu_top CLK_DOUT_CMU_BUSC_BUSPHSI2C>;	/* CAL:cmucal-node.c:593 { OSCCLK_BUSC, CLKCMU_BUSC_BUSPHSI2C } */
			clock-names = "oscclk", "bus", "busphsi2c";
			status = "disabled";
		};

		pinctrl_busc: pinctrl@15a30000 {
			compatible = "samsung,exynos8895-pinctrl";
			reg = <0x15a30000 0x1000>;
			interrupts = <GIC_SPI 103 IRQ_TYPE_LEVEL_HIGH>;
		};

		cmu_top: clock-controller@15a80000 {
			compatible = "samsung,exynos8895-cmu-top";
			reg = <0x15a80000 0x8000>;
			#clock-cells = <1>;
			clocks = <&oscclk>;
			clock-names = "oscclk";
		};

		adc: adc@15b70000 {
			compatible = "samsung,exynos8895-adc";	/* stock "samsung,exynos-adc-v3" FDT:7616 */
			reg = <0x15b70000 0x100>;			/* FDT:7617 */
			interrupts = <GIC_SPI 104 IRQ_TYPE_LEVEL_HIGH>;	/* FDT:7618 <0 0x68 0> */
			/* FDT:7621 <0x21 0x3f2> = GATE_ADCIF_BUSC_S0 (S:include/dt-bindings/clock/exynos8895.h:453) */
			clocks = <&cmu_busc CLK_GOUT_BUSC_ADCIF_BUSC_PCLK_S0>;
			clock-names = "adc";
			#io-channel-cells = <1>;			/* FDT:7619 */
			/* no vdd-supply: stock has none (FDT:7615-7625) */
			status = "disabled";
		};

		cmu_apm: clock-controller@16400000 {
			compatible = "samsung,exynos8895-cmu-apm";
			reg = <0x16400000 0x8000>;	/* CAL:cmucal-sfr.c:9 SFR_BLOCK(APM, 0x16400000, 0x8000) */
			#clock-cells = <1>;
			clocks = <&oscclk>,	/* CAL:cmucal-node.c:581 parents { OSCCLK_APM, CLKCMU_APM_BUS } */
				 <&cmu_top CLK_DOUT_CMU_APM_BUS>;
			clock-names = "oscclk", "bus";
		};

		ap2apm_mailbox: mailbox@16440000 {
			compatible = "samsung,exynos8895-mbox";
			/* S:arch/arm64/boot/dts/exynos/exynos8895.dtsi:2420 "<0x0 0x16440000 0x1000>," (AP2APM MAILBOX); FDT:6687 */
			reg = <0x16440000 0x1000>;
			/*
			 * CMU_APM MAILBOX_APM2AP pclk, APM+0x2038 bit 21
			 * (CAL:cmucal-sfr.c:147); the driver holds it enabled.
			 */
			clocks = <&cmu_apm CLK_GOUT_APM_MAILBOX_APM2AP_PCLK>;
			clock-names = "pclk";
			/* S:arch/arm64/boot/dts/exynos/exynos8895.dtsi:2419 "interrupts = <0 39 0>;"; FDT:6686 */
			interrupts = <GIC_SPI 39 IRQ_TYPE_LEVEL_HIGH>;
			#mbox-cells = <0>;
			status = "disabled";
		};

		pmu_system_controller: system-controller@16480000 {
			compatible = "samsung,exynos8895-pmu",
				     "samsung,exynos7-pmu", "syscon";
			reg = <0x16480000 0x10000>;

			/*
			 * S-Boot boot target in INFORM3 (0x080c) for the stock
			 * commands (S:drivers/staging/samsung/sec_reboot.c:47-60,
			 * 170-226; offset S:include/linux/sec_ext.h:28). No
			 * mode-normal: INFORM2 and the NULL/unknown-command default
			 * 0x12345670 come from the PMU driver's priority-128 reboot
			 * notifier, which runs before this node's (priority 0), so
			 * this node only overrides INFORM3 for a matching command;
			 * a power-off (cmd NULL -> "normal") writes nothing, as
			 * stock sec_power_off() writes no INFORM3.
			 */
			reboot-mode {
				compatible = "syscon-reboot-mode";
				offset = <0x080c>;
				mode-download = <0x12345671>;	/* SEC_RESET_REASON_DOWNLOAD :51,178-179 */
				mode-upload = <0x12345672>;	/* SEC_RESET_REASON_UPLOAD :52,182-183 */
				mode-recovery = <0x12345674>;	/* SEC_RESET_REASON_RECOVERY :54,176-177 */
				mode-fota = <0x12345675>;	/* SEC_RESET_REASON_FOTA :55,172-173 */
				mode-fota_bl = <0x12345676>;	/* SEC_RESET_REASON_FOTA_BL :56,174-175 */
				mode-secure = <0x12345677>;	/* SEC_RESET_REASON_SECURE :57,184-185 */
				mode-fwup = <0x12345679>;	/* SEC_RESET_REASON_FWUP :58,186-187 */
				mode-bootloader = <0x1234567d>;	/* SEC_RESET_REASON_BOOTLOADER :60,180-181 */
			};

			/*
			 * MIPI D-PHYs: DSIM0 isolation at PMU+0x710 bit 0 (FDT:7476
			 * "isolation = <0x710>;", S:drivers/phy/phy-exynos8895-mipi.c:25
			 * EXYNOS_MIPI_PHY_ISO_BYPASS (1 << 0)); the PHY driver takes
			 * this node's parent as its PMU regmap.
			 */
			mipi_phy: mipi-phy {
				compatible = "samsung,exynos8895-mipi-video-phy";
				#phy-cells = <1>;
				status = "disabled";
			};
		};

		/*
		 * Power domains (spec/L1_platform.md 4.4). CONFIGURATION at reg + 0,
		 * STATUS + 4, OPTION + 8: S:arch/arm64/boot/dts/exynos/exynos8895-pm-domains.dtsi:18-135
		 * = CAL:pmucal_local_exynos8895.h <blk>_CONFIGURATION (CAL: =
		 * S:drivers/soc/samsung/cal-if/exynos8895/). Every node is added
		 * "disabled" (plan 2.3 D2). A board enables the nine whose stock
		 * on/off is CONFIGURATION/STATUS only and that host no DMA master
		 * S-Boot leaves running (cam dsp g2d isphq isplp mfc vpu dcam srdz,
		 * L1 4.4) once its PMU node is enabled (lpm_init before any
		 * power-off); a domain without a consumer is then switched off at
		 * sync_state. The other seven stay as S-Boot left them until their
		 * consumer layer enables them with its devices.
		 */
		pd_abox: power-domain@16484000 {
			compatible = "samsung,exynos8895-pd", "samsung,exynos5433-pd";
			reg = <0x16484000 0x20>;	/* S:...-pm-domains.dtsi:18-24; CAL:pmucal_local_exynos8895.h:2 */
			#power-domain-cells = <0>;
			label = "abox";
			samsung,pmu-syscon = <&pmu_system_controller>;	/* ABOX_CA7_OPTION before off: CAL:...:62 */
			status = "disabled";	/* L6E: enabled with ABOX */
		};

		pd_cam: power-domain@16484020 {
			compatible = "samsung,exynos8895-pd", "samsung,exynos5433-pd";
			reg = <0x16484020 0x20>;	/* S:...-pm-domains.dtsi:26-31; CAL:...:72 */
			#power-domain-cells = <0>;
			label = "cam";
			status = "disabled";	/* L1 4.4: enabled by the board (greatlte: -l1.dtsi) */
		};

		pd_dbg: power-domain@16484040 {
			compatible = "samsung,exynos8895-pd", "samsung,exynos5433-pd";
			reg = <0x16484040 0x20>;	/* S:...-pm-domains.dtsi:33-38; CAL:...:124 */
			#power-domain-cells = <0>;
			label = "dbg";
			status = "disabled";	/* S:...-pm-domains.dtsi:37 status = "disabled" */
		};

		pd_dpu0: power-domain@16484060 {
			compatible = "samsung,exynos8895-pd", "samsung,exynos5433-pd";
			reg = <0x16484060 0x20>;	/* S:...-pm-domains.dtsi:48-53; CAL:...:199 */
			#power-domain-cells = <0>;
			label = "dpu0";
			status = "disabled";	/* L5: live splash (DECON DMA) */
		};

		pd_dpu1: power-domain@16484080 {
			compatible = "samsung,exynos8895-pd", "samsung,exynos5433-pd";
			reg = <0x16484080 0x20>;	/* S:...-pm-domains.dtsi:55-61; CAL:...:243 */
			#power-domain-cells = <0>;
			label = "dpu1";
			power-domains = <&pd_dpu0>;	/* S:...-pm-domains.dtsi:60 parent = <&pd_dpu0> */
			status = "disabled";	/* L5 */
		};

		pd_dsp: power-domain@164840a0 {
			compatible = "samsung,exynos8895-pd", "samsung,exynos5433-pd";
			reg = <0x164840a0 0x20>;	/* S:...-pm-domains.dtsi:63-68; CAL:...:280 */
			#power-domain-cells = <0>;
			label = "dsp";
			status = "disabled";	/* L1 4.4: enabled by the board (greatlte: -l1.dtsi) */
		};

		pd_g2d: power-domain@164840c0 {
			compatible = "samsung,exynos8895-pd", "samsung,exynos5433-pd";
			reg = <0x164840c0 0x20>;	/* S:...-pm-domains.dtsi:70-75; CAL:...:315 */
			#power-domain-cells = <0>;
			label = "g2d";
			status = "disabled";	/* L1 4.4: enabled by the board (greatlte: -l1.dtsi) */
		};

		pd_g3d: power-domain@164840e0 {
			compatible = "samsung,exynos8895-pd", "samsung,exynos5433-pd";
			/*
			 * reg 1 = CMU_G3D, the PLL/mux words of g3d_on/g3d_off:
			 * CAL:...:358-360,371-373; CAL:cmucal-sfr.c:25
			 */
			reg = <0x164840e0 0x20>,	/* S:...-pm-domains.dtsi:77-82; CAL:...:361 */
			      <0x13800000 0x1000>;
			#power-domain-cells = <0>;
			label = "g3d";
			status = "disabled";	/* L6A: enabled with the GPU */
		};

		pd_isphq: power-domain@16484100 {
			compatible = "samsung,exynos8895-pd", "samsung,exynos5433-pd";
			reg = <0x16484100 0x20>;	/* S:...-pm-domains.dtsi:84-90; CAL:...:381 */
			#power-domain-cells = <0>;
			label = "isphq";
			power-domains = <&pd_cam>;	/* S:...-pm-domains.dtsi:89 parent = <&pd_cam> */
			status = "disabled";	/* L1 4.4: enabled by the board (greatlte: -l1.dtsi) */
		};

		pd_isplp: power-domain@16484120 {
			compatible = "samsung,exynos8895-pd", "samsung,exynos5433-pd";
			reg = <0x16484120 0x20>;	/* S:...-pm-domains.dtsi:92-98; CAL:...:412 */
			#power-domain-cells = <0>;
			label = "isplp";
			power-domains = <&pd_isphq>;	/* S:...-pm-domains.dtsi:97 parent = <&pd_isphq> */
			status = "disabled";	/* L1 4.4: enabled by the board (greatlte: -l1.dtsi) */
		};

		pd_iva: power-domain@16484140 {
			compatible = "samsung,exynos8895-pd", "samsung,exynos5433-pd";
			reg = <0x16484140 0x20>;	/* S:...-pm-domains.dtsi:100-105; CAL:...:447 */
			#power-domain-cells = <0>;
			label = "iva";
			status = "disabled";	/* off clears VMCU_CTRL/PMU at 0x136d0000 first: CAL:...:486-491 */
		};

		pd_mfc: power-domain@16484160 {
			compatible = "samsung,exynos8895-pd", "samsung,exynos5433-pd";
			reg = <0x16484160 0x20>;	/* S:...-pm-domains.dtsi:107-112; CAL:...:498 */
			#power-domain-cells = <0>;
			label = "mfc";
			status = "disabled";	/* L1 4.4: enabled by the board (greatlte: -l1.dtsi) */
		};

		pd_vpu: power-domain@16484180 {
			compatible = "samsung,exynos8895-pd", "samsung,exynos5433-pd";
			reg = <0x16484180 0x20>;	/* S:...-pm-domains.dtsi:122-127; CAL:...:567 */
			#power-domain-cells = <0>;
			label = "vpu";
			status = "disabled";	/* L1 4.4: enabled by the board (greatlte: -l1.dtsi) */
		};

		pd_vts: power-domain@164841a0 {
			compatible = "samsung,exynos8895-pd", "samsung,exynos5433-pd";
			reg = <0x164841a0 0x20>;	/* S:...-pm-domains.dtsi:129-135; CAL:...:599 */
			#power-domain-cells = <0>;
			label = "vts";
			status = "disabled";	/* L6E: enabled with VTS; CMUREF mux before off: CAL:...:637-638 */
		};

		pd_dcam: power-domain@16485220 {
			compatible = "samsung,exynos8895-pd", "samsung,exynos5433-pd";
			reg = <0x16485220 0x20>;	/* S:...-pm-domains.dtsi:40-46; CAL:...:168 */
			#power-domain-cells = <0>;
			label = "dcam";
			power-domains = <&pd_srdz>;	/* S:...-pm-domains.dtsi:45 parent = <&pd_srdz> */
			status = "disabled";	/* L1 4.4: enabled by the board (greatlte: -l1.dtsi) */
		};

		pd_srdz: power-domain@16485420 {
			compatible = "samsung,exynos8895-pd", "samsung,exynos5433-pd";
			reg = <0x16485420 0x20>;	/* S:...-pm-domains.dtsi:114-120; CAL:...:532 */
			#power-domain-cells = <0>;
			label = "srdz";
			power-domains = <&pd_isplp>;	/* S:...-pm-domains.dtsi:119 parent = <&pd_isplp> */
			status = "disabled";	/* L1 4.4: enabled by the board (greatlte: -l1.dtsi) */
		};

		pinctrl_alive: pinctrl@164b0000 {
			compatible = "samsung,exynos8895-pinctrl";
			reg = <0x164b0000 0x1000>;

			wakeup-interrupt-controller {
				compatible = "samsung,exynos8895-wakeup-eint",
					     "samsung,exynos7-wakeup-eint";
				interrupt-parent = <&gic>;
				interrupts = <GIC_SPI 16 IRQ_TYPE_LEVEL_HIGH>;
			};
		};

		apm_sram: sram@16500000 {
			compatible = "mmio-sram";
			/* S:arch/arm64/boot/dts/exynos/exynos8895.dtsi:2421 "<0x0 0x16500000 0xB400>;" (APM SRAM); FDT:6687 */
			reg = <0x16500000 0xb400>;
			#address-cells = <1>;
			#size-cells = <1>;
			ranges = <0x0 0x16500000 0xb400>;
			/*
			 * Device mapping only: the ACPM driver maps it with devm_ioremap()
			 * (A:drivers/firmware/samsung/exynos-acpm.c:624) as stock
			 * (S:drivers/soc/samsung/acpm/acpm_ipc.c:725); without this the
			 * SRAM driver would add a write-combined mapping
			 * (A:drivers/misc/sram.c:391-399).
			 */
			no-memory-wc;
			status = "disabled";
		};

		cmu_cpucl0: clock-controller@16800000 {
			compatible = "samsung,exynos8895-cmu-cpucl0";
			reg = <0x16800000 0x8000>;	/* CAL:cmucal-sfr.c:15 SFR_BLOCK(CPUCL0, 0x16800000, 0x8000) */
			#clock-cells = <1>;
			clocks = <&oscclk>,
				 <&cmu_top CLK_DOUT_CMU_CPUCL0_SWITCH>,	/* CAL:cmucal-node.c:621 { OSCCLK_CPUCL0, CLKCMU_CPUCL0_SWITCH } */
				 <&cmu_top CLK_DOUT_CMU_HPM>,	/* CAL:cmucal-node.c:1567 parent CLKCMU_HPM */
				 <&cmu_top CLK_GOUT_CMU_DROOPDETECTOR>;	/* CAL:cmucal-node.c:1570-1571 parent CLKCMU_DROOPDETECTOR */
			clock-names = "oscclk", "switch", "hpm", "droop";
		};

		cmu_cpucl1: clock-controller@16900000 {
			compatible = "samsung,exynos8895-cmu-cpucl1";
			reg = <0x16900000 0x8000>;	/* CAL:cmucal-sfr.c:16 SFR_BLOCK(CPUCL1, 0x16900000, 0x8000) */
			#clock-cells = <1>;
			clocks = <&oscclk>,
				 <&cmu_top CLK_DOUT_CMU_CPUCL1_SWITCH>,	/* CAL:cmucal-node.c:1002 MUX_CLKCMU_CPUCL1_SWITCH_USER parents */
				 <&cmu_top CLK_DOUT_CMU_HPM>;	/* CAL:cmucal-node.c:1580 parent CLKCMU_HPM */
			clock-names = "oscclk", "switch", "hpm";
		};
	};

	/*
	 * Trips from the factory DT (FDT:9436-9748) and, for little, the ECT
	 * (spec/L2c_thermal.md 2.3). Stock "hot" 115 C, its level-7 threshold with
	 * the hardware trip armed, is the critical trip here (the driver needs one
	 * and programs it at level 7). Stock's power_allocator switch-on trips
	 * (55 C big, 78 C GPU) were "active"; ACK takes the switch-on from the first
	 * of two passive trips, walked in DT order, so they are passive and come
	 * first (A:drivers/thermal/gov_power_allocator.c:500-536). The governor and
	 * gains are on the TMU nodes (samsung,ipa-*); the driver selects
	 * power_allocator once the zone's cooling devices are power actors
	 * (spec/L2c_thermal.md 4.2); until then these zones run step_wise.
	 */
	thermal-zones {
		big-thermal {
			polling-delay-passive = <50>;	/* FDT:9440 <0x32> */
			polling-delay = <1000>;		/* FDT:9441 <0x3e8> */
			thermal-sensors = <&tmu_big>;
			sustainable-power = <2000>;	/* FDT:9444 <0x7d0> */

			trips {
				big_switch_on: big-switch-on {
					temperature = <55000>;	/* FDT:9460 mngs-alert0 <0xd6d8> */
					hysteresis = <2000>;	/* FDT:9461 <0x7d0> */
					type = "passive";	/* stock "active", see above */
				};

				big_passive: big-passive {
					temperature = <83000>;	/* FDT:9468 mngs-alert1 <0x14438> */
					hysteresis = <5000>;	/* FDT:9469 <0x1388> */
					type = "passive";
				};

				big-crit {
					temperature = <115000>;	/* FDT:9476 mngs-hot <0x1c138> */
					hysteresis = <5000>;	/* FDT:9477 */
					type = "critical";
				};
			};

			cooling-maps {
				map0 {
					trip = <&big_passive>;
					cooling-device = <&cpu4 THERMAL_NO_LIMIT THERMAL_NO_LIMIT>,
							 <&cpu5 THERMAL_NO_LIMIT THERMAL_NO_LIMIT>,
							 <&cpu6 THERMAL_NO_LIMIT THERMAL_NO_LIMIT>,
							 <&cpu7 THERMAL_NO_LIMIT THERMAL_NO_LIMIT>;
				};
			};
		};

		/*
		 * Stock APOLLO zone: the ECT THERMAL function "APOLLO" (sboot.bin
		 * SB:0x508d8) overrides the trip temperatures (its lower bounds, equal
		 * to FDT:9505-9562) and the upper limit of each map's <&cpu0 0 0>
		 * (FDT:9573-9608) with the cpufreq level of its max_frequency
		 * (S:drivers/thermal/of-thermal.c:541-634): 1690000, 1690000, 1456000,
		 * 1248000, 1053000, 598000, 598000 kHz = states 0, 0, 1, 2, 3, 7, 7 of
		 * the little table (cpucl1_opp_table, descending). step_wise, as stock
		 * (no governor property, IKC:2520).
		 */
		little-thermal {
			polling-delay-passive = <0>;	/* FDT:9498 */
			polling-delay = <0>;		/* FDT:9499 */
			thermal-sensors = <&tmu_little>;

			trips {
				little_alert0: little-alert0 {
					temperature = <20000>;	/* ECT SB:0x508dc; FDT:9505 */
					hysteresis = <5000>;	/* FDT:9506 */
					type = "active";
				};

				little_alert1: little-alert1 {
					temperature = <76000>;	/* ECT SB:0x508f0; FDT:9513 */
					hysteresis = <5000>;
					type = "active";
				};

				little_alert2: little-alert2 {
					temperature = <81000>;	/* ECT SB:0x50904; FDT:9521 */
					hysteresis = <5000>;
					type = "active";
				};

				little_alert3: little-alert3 {
					temperature = <86000>;	/* ECT SB:0x50918; FDT:9529 */
					hysteresis = <5000>;
					type = "active";
				};

				little_alert4: little-alert4 {
					temperature = <91000>;	/* ECT SB:0x5092c; FDT:9537 */
					hysteresis = <5000>;
					type = "active";
				};

				little_alert5: little-alert5 {
					temperature = <96000>;	/* ECT SB:0x50940; FDT:9545 */
					hysteresis = <5000>;
					type = "active";
				};

				little_alert6: little-alert6 {
					temperature = <101000>;	/* ECT SB:0x50954; FDT:9553 */
					hysteresis = <5000>;
					type = "active";
				};

				little-crit {
					temperature = <115000>;	/* FDT:9561 apo-hot; ECT SB:0x50968 */
					hysteresis = <5000>;
					type = "critical";
				};
			};

			cooling-maps {
				map0 {
					trip = <&little_alert0>;
					cooling-device = <&cpu0 0 0>;	/* 1690000 */
				};

				map1 {
					trip = <&little_alert1>;
					cooling-device = <&cpu0 0 0>;	/* 1690000 */
				};

				map2 {
					trip = <&little_alert2>;
					cooling-device = <&cpu0 0 1>;	/* 1456000 */
				};

				map3 {
					trip = <&little_alert3>;
					cooling-device = <&cpu0 0 2>;	/* 1248000 */
				};

				map4 {
					trip = <&little_alert4>;
					cooling-device = <&cpu0 0 3>;	/* 1053000 */
				};

				map5 {
					trip = <&little_alert5>;
					cooling-device = <&cpu0 0 7>;	/* 598000 */
				};

				map6 {
					trip = <&little_alert6>;
					cooling-device = <&cpu0 0 7>;	/* 598000 */
				};
			};
		};

		gpu-thermal {
			polling-delay-passive = <100>;	/* FDT:9615 <0x64> */
			polling-delay = <0>;		/* FDT:9616 */
			thermal-sensors = <&tmu_gpu>;
			sustainable-power = <2000>;	/* FDT:9619 <0x7d0> */

			trips {
				gpu_switch_on: gpu-switch-on {
					temperature = <78000>;	/* FDT:9635 gpu-alert0 <0x130b0> */
					hysteresis = <2000>;	/* FDT:9636 <0x7d0> */
					type = "passive";	/* stock "active", see above */
				};

				gpu_passive: gpu-passive {
					temperature = <88000>;	/* FDT:9643 gpu-alert1 <0x157c0> */
					hysteresis = <5000>;	/* FDT:9644 */
					type = "passive";
				};

				gpu-crit {
					temperature = <115000>;	/* FDT:9651 gpu-hot */
					hysteresis = <5000>;
					type = "critical";
				};
			};
			/* the cooling map to the GPU devfreq device is the GPU layer's */
		};

		isp-thermal {
			polling-delay-passive = <0>;	/* FDT:9673 */
			polling-delay = <0>;		/* FDT:9674 */
			thermal-sensors = <&tmu_isp>;

			trips {
				isp-crit {
					temperature = <115000>;	/* FDT:9712 isp-hot */
					hysteresis = <5000>;
					type = "critical";
				};
			};
		};
	};

	timer {
		compatible = "arm,armv8-timer";
		/* Hypervisor Virtual Timer interrupt is not wired to GIC */
		interrupts = <GIC_PPI 13 (GIC_CPU_MASK_SIMPLE(8) | IRQ_TYPE_LEVEL_LOW)>,
			     <GIC_PPI 14 (GIC_CPU_MASK_SIMPLE(8) | IRQ_TYPE_LEVEL_LOW)>,
			     <GIC_PPI 11 (GIC_CPU_MASK_SIMPLE(8) | IRQ_TYPE_LEVEL_LOW)>,
			     <GIC_PPI 10 (GIC_CPU_MASK_SIMPLE(8) | IRQ_TYPE_LEVEL_LOW)>;
		/*
		 * Non-updatable, broken stock Samsung bootloader does not
		 * configure CNTFRQ_EL0
		 */
		clock-frequency = <26000000>;
	};
};

#include "exynos8895-pinctrl.dtsi"
#include "arm/samsung/exynos-syscon-restart.dtsi"

&poweroff {
	/*
	 * Stock power-off clears only PS_HOLD_CONTROL bit 8
	 * (S:drivers/staging/samsung/sec_reboot.c:147
	 * "exynos_pmu_update(EXYNOS_PMU_PS_HOLD_CONTROL, 0x1<<8, 0x0);",
	 * S:drivers/soc/samsung/exynos-reboot.c:77,188 0x330C "& 0xFFFFFEFF").
	 * The common node's "mask" alone writes the whole word 0x5200
	 * (A:drivers/power/reset/syscon-poweroff.c:71-74).
	 */
	mask = <0x100>;
	value = <0x0>;
};

/*
 * CPU DVFS: the stock cpufreq domains, domain@0 = cpus 0-3 with cal-id
 * ACPM_DVFS_CPUCL1 and domain@1 = cpus 4-7 with ACPM_DVFS_CPUCL0
 * (S:arch/arm64/boot/dts/exynos/exynos8895.dtsi:467-470, 512-515);
 * "#cooling-cells = <2>;" (:188, :225).
 */
&cpu0 {
	clocks = <&acpm_ipc EXYNOS8895_CLK_ACPM_DVFS_CPUCL1>;
	operating-points-v2 = <&cpucl1_opp_table>;
	#cooling-cells = <2>;
};

&cpu1 {
	clocks = <&acpm_ipc EXYNOS8895_CLK_ACPM_DVFS_CPUCL1>;
	operating-points-v2 = <&cpucl1_opp_table>;
	#cooling-cells = <2>;
};

&cpu2 {
	clocks = <&acpm_ipc EXYNOS8895_CLK_ACPM_DVFS_CPUCL1>;
	operating-points-v2 = <&cpucl1_opp_table>;
	#cooling-cells = <2>;
};

&cpu3 {
	clocks = <&acpm_ipc EXYNOS8895_CLK_ACPM_DVFS_CPUCL1>;
	operating-points-v2 = <&cpucl1_opp_table>;
	#cooling-cells = <2>;
};

&cpu4 {
	clocks = <&acpm_ipc EXYNOS8895_CLK_ACPM_DVFS_CPUCL0>;
	operating-points-v2 = <&cpucl0_opp_table>;
	#cooling-cells = <2>;
	/* ECT GEN DTM_PWR_Coeff[0] (MNGS), sboot.bin SB:0x4b288; S:drivers/thermal/samsung/exynos_tmu.c:1380-1393 */
	dynamic-power-coefficient = <465>;
};

&cpu5 {
	clocks = <&acpm_ipc EXYNOS8895_CLK_ACPM_DVFS_CPUCL0>;
	operating-points-v2 = <&cpucl0_opp_table>;
	#cooling-cells = <2>;
	dynamic-power-coefficient = <465>;
};

&cpu6 {
	clocks = <&acpm_ipc EXYNOS8895_CLK_ACPM_DVFS_CPUCL0>;
	operating-points-v2 = <&cpucl0_opp_table>;
	#cooling-cells = <2>;
	dynamic-power-coefficient = <465>;
};

&cpu7 {
	clocks = <&acpm_ipc EXYNOS8895_CLK_ACPM_DVFS_CPUCL0>;
	operating-points-v2 = <&cpucl0_opp_table>;
	#cooling-cells = <2>;
	dynamic-power-coefficient = <465>;
};
